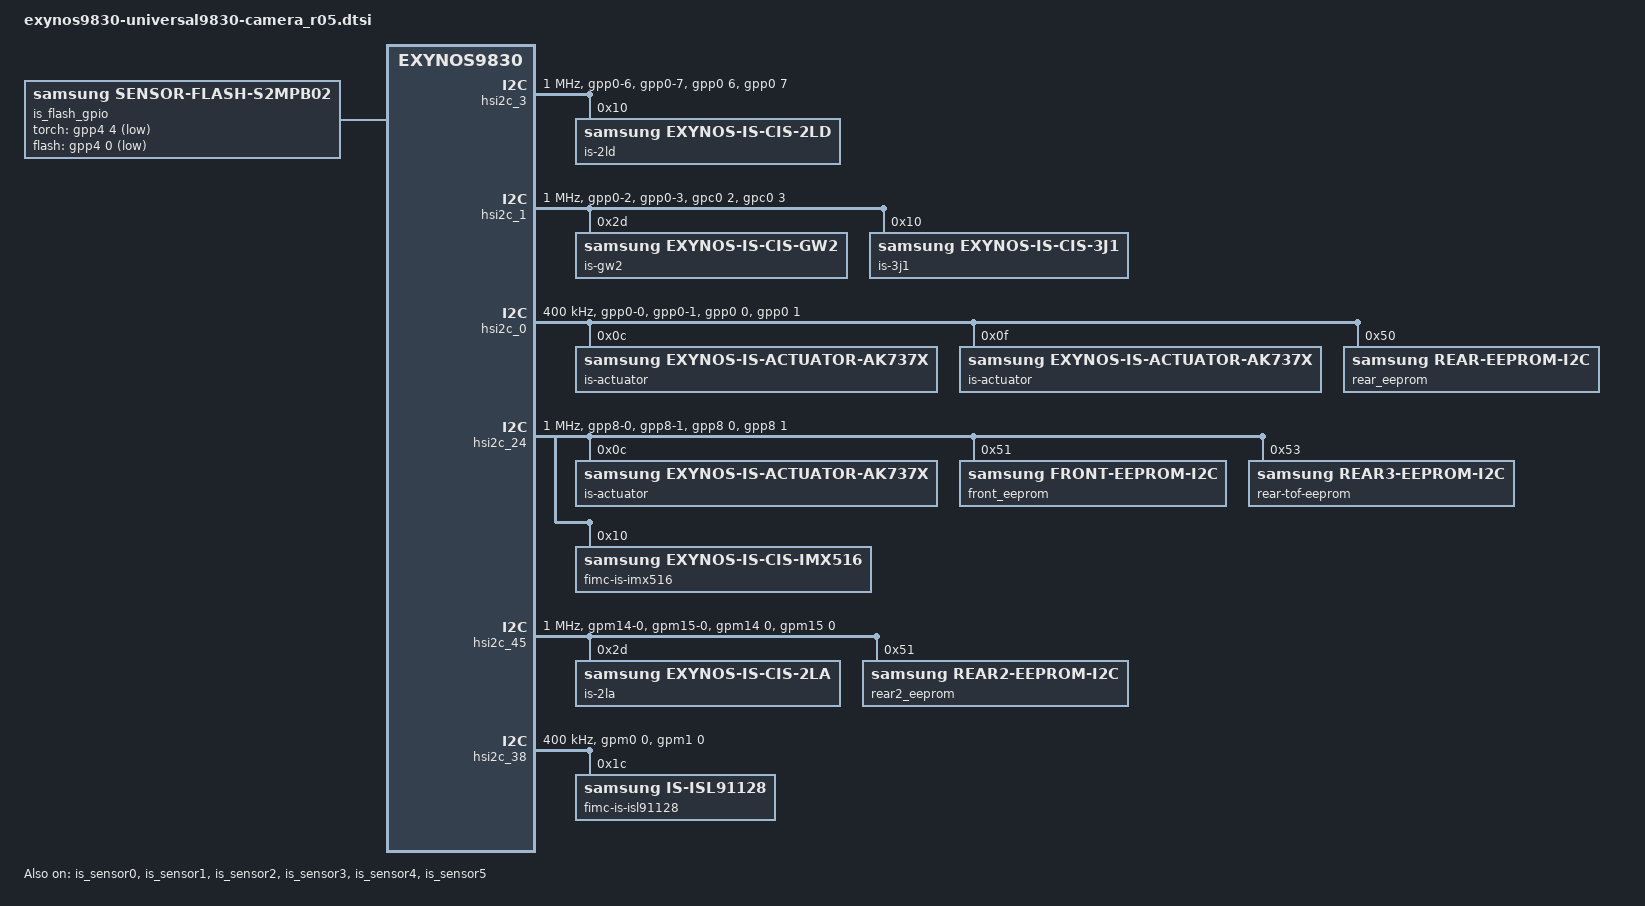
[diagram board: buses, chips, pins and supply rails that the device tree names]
/*
 * Samsung Exynos SoC series Pablo driver
 *
 * Copyright (c) 2019 Samsung Electronics Co., Ltd
 *
 * This program is free software; you can redistribute it and/or modify
 * it under the terms of the GNU General Public License version 2 as
 * published by the Free Software Foundation.
 */

#include <dt-bindings/camera/exynos_is_dt.h>
#include <dt-bindings/interrupt-controller/exynos9830.h>
#include <dt-bindings/clock/exynos9830.h>

#include "camera/module_2ld.dtsi"
#include "camera/module_3j1.dtsi"
#include "camera/module_2la.dtsi"
#include "camera/module_gw2.dtsi"
#include "camera/module_imx516.dtsi"

/ {
	fragment@camera {
		target-path = "/";
		__overlay__ {
			/* REAR CAMERA */
			is_sensor_2ld: is_sensor_2ld@20 {
				pinctrl-names = "pin0", "pin1", "pin2", "release";
				pinctrl-0 = <>;
				pinctrl-1 = <&sensor_mclk0_out>;
				pinctrl-2 = <&sensor_mclk0_fn>;
				pinctrl-3 = <>;

				/* board */
				position = <0>;	/* Rear:0. Front:1. Rear_sub:2. Secure:3. */
				id = <0>; /* is_sensor id */
				mclk_ch = <0>;
				sensor_i2c_ch = <0>; /* SENSOR_CONTROL_I2C0 */

				/* vendor */
				rom_type = <2>; /* ROM_TYPE_EEPROM */
				rom_id = <0>;
				rom_cal_index = <0>;

				/* peri */
				af {
					product_name = <18>; /* ACTUATOR_NAME_AK737X : ak7371 or ak7374 */
					i2c_ch = <1>; /* SENSOR_CONTROL_I2C1 */
				};

				flash {
					product_name = <11>; /* FLASH_GPIO */
				};

				ois {
					product_name = <100>; /* NOTHING */
				};

				mcu {
					product_name = <1>; /* STM32 */
					i2c_addr = <0x51>;
					i2c_ch = <1>; /* SENSOR_CONTROL_I2C1 */
				};

				aperture {
					product_name = <100>; /* NOTHING */
				};

				vc_extra {
					/* ex) statX = <stat_type, sensor_mode, max_width, max_height, max_element> */
					stat0 = </* not avaliable */>;									/* VC_BUF_DATA_TYPE_SENSOR_STAT1 */
					stat1 = </*VC_STAT_TYPE_PDP_1_1_PDAF_STAT0*/ 800 /*VC_SENSOR_MODE_2PD_MODE3*/ 102 512 84 1>;	/* VC_BUF_DATA_TYPE_GENERAL_STAT1 */
					stat2 = </* not avaliable */>;									/* VC_BUF_DATA_TYPE_SENSOR_STAT2 */
					stat3 = </*VC_STAT_TYPE_PDP_1_1_PDAF_STAT1*/ 801 /*VC_SENSOR_MODE_2PD_MODE3*/ 102 512 84 1>;	/* VC_BUF_DATA_TYPE_GENERAL_STAT2 */
				};

				power_seq {
					use = <1>;
					gpio_mclk = <&gpc0 0 0x1>;

					scenario_normal_on {
						sensor_scenario = <SENSOR_SCENARIO_NORMAL>;
						gpio_scenario = <GPIO_SCENARIO_ON>;

						/* A start node number should be over the 10 for reserved number 0~9. */
						/* pname = "name"; pin = <act value delay voltage>; gpio = <gpx# # 0x1>; */
						20 { pname = "VDDIO_1.8V_CAM"; pin = <PIN_REGULATOR 1 300>; share = <SRT_ACQUIRE SHARED_PIN6 1>; };
						85 { pname = "VDD_VM_2.8V_OIS"; pin = <PIN_REGULATOR 1 100>; share = <SRT_ACQUIRE SHARED_PIN3 1>; };
						86 { pname = "VDDD_1.8V_OIS"; pin = <PIN_REGULATOR 1 0>; share = <SRT_ACQUIRE SHARED_PIN2 1>; };
						100 { pname = "pin"; pin = <PIN_FUNCTION 2 0>; share = <SRT_ACQUIRE SHARED_PIN0 1>; };
						110 { pname = "MCLK"; pin = <PIN_MCLK 1 1500>; share = <SRT_ACQUIRE SHARED_PIN8 1>; };
						125 { pname = "ois_rst high"; pin = <PIN_OUTPUT 1 20000>; gpio = <&gpp9 3 0x1>; share = <SRT_ACQUIRE SHARED_PIN1 1>; };
					};

					scenario_vision_on {
						sensor_scenario = <SENSOR_SCENARIO_VISION>;
						gpio_scenario = <GPIO_SCENARIO_ON>;

						/* A start node number should be over the 10 for reserved number 0~9. */
						/* pname = "name"; pin = <act value delay voltage>; gpio = <gpx# # 0x1>; */
						20 { pname = "VDDIO_1.8V_CAM"; pin = <PIN_REGULATOR 1 300>; share = <SRT_ACQUIRE SHARED_PIN6 1>; };
						85 { pname = "VDD_VM_2.8V_OIS"; pin = <PIN_REGULATOR 1 100>; share = <SRT_ACQUIRE SHARED_PIN3 1>; };
						86 { pname = "VDDD_1.8V_OIS"; pin = <PIN_REGULATOR 1 0>; share = <SRT_ACQUIRE SHARED_PIN2 1>; };
						100 { pname = "pin"; pin = <PIN_FUNCTION 2 0>; share = <SRT_ACQUIRE SHARED_PIN0 1>; };
						110 { pname = "MCLK"; pin = <PIN_MCLK 1 1500>; share = <SRT_ACQUIRE SHARED_PIN8 1>; };
						125 { pname = "ois_rst high"; pin = <PIN_OUTPUT 1 20000>; gpio = <&gpp9 3 0x1>; share = <SRT_ACQUIRE SHARED_PIN1 1>; };
					};

					scenario_hw_init_normal_on {
						/* HW INIT (without ois power control) */
					};

					scenario_normal_off {
						sensor_scenario = <SENSOR_SCENARIO_NORMAL>;
						gpio_scenario = <GPIO_SCENARIO_OFF>;

						/* A start node number should be over the 10 for reserved number 0~9. */
						/* pname = "name"; pin = <act value delay voltage>; gpio = <gpx# # 0x1>; */
						60 { pname = "MCLK"; pin = <PIN_MCLK 0 0>; share = <SRT_RELEASE SHARED_PIN8 0>; };
						80 { pname = "pin"; pin = <PIN_FUNCTION 1 0>; share = <SRT_RELEASE SHARED_PIN0 0>; };
						105 { pname = "ois_rst low"; pin = <PIN_OUTPUT 0 0>; gpio = <&gpp9 3 0x1>; share = <SRT_RELEASE SHARED_PIN1 0>; };
						115 { pname = "VDDD_1.8V_OIS"; pin = <PIN_REGULATOR 0 0>; share = <SRT_RELEASE SHARED_PIN2 0>; };
						116 { pname = "VDD_VM_2.8V_OIS"; pin = <PIN_REGULATOR 0 0>; share = <SRT_RELEASE SHARED_PIN3 0>; };
						130 { pname = "VDDIO_1.8V_CAM"; pin = <PIN_REGULATOR 0 10>; share = <SRT_RELEASE SHARED_PIN6 0>; };
					};

					scenario_vision_off {
						sensor_scenario = <SENSOR_SCENARIO_VISION>;
						gpio_scenario = <GPIO_SCENARIO_OFF>;

						/* A start node number should be over the 10 for reserved number 0~9. */
						/* pname = "name"; pin = <act value delay voltage>; gpio = <gpx# # 0x1>; */
						60 { pname = "MCLK"; pin = <PIN_MCLK 0 0>; share = <SRT_RELEASE SHARED_PIN8 0>; };
						80 { pname = "pin"; pin = <PIN_FUNCTION 1 0>; share = <SRT_RELEASE SHARED_PIN0 0>; };
						105 { pname = "ois_rst low"; pin = <PIN_OUTPUT 0 0>; gpio = <&gpp9 3 0x1>; share = <SRT_RELEASE SHARED_PIN1 0>; };
						115 { pname = "VDDD_1.8V_OIS"; pin = <PIN_REGULATOR 0 0>; share = <SRT_RELEASE SHARED_PIN2 0>; };
						116 { pname = "VDD_VM_2.8V_OIS"; pin = <PIN_REGULATOR 0 0>; share = <SRT_RELEASE SHARED_PIN3 0>; };
						130 { pname = "VDDIO_1.8V_CAM"; pin = <PIN_REGULATOR 0 10>; share = <SRT_RELEASE SHARED_PIN6 0>; };
					};

					scenario_retention_on {
						sensor_scenario = <SENSOR_SCENARIO_NORMAL>;
						gpio_scenario = <GPIO_SCENARIO_SENSOR_RETENTION_ON>;

						/* A start node number should be over the 10 for reserved number 0~9. */
						/* pname = "name"; pin = <act value delay voltage>; gpio = <gpx# # 0x1>; */
						20 { pname = "MCLK"; pin = <PIN_MCLK 0 0>; share = <SRT_RELEASE SHARED_PIN8 0>; };
						40 { pname = "pin"; pin = <PIN_FUNCTION 1 0>; share = <SRT_RELEASE SHARED_PIN0 0>; };
						105 { pname = "ois_rst low"; pin = <PIN_OUTPUT 0 0>;  gpio = <&gpp9 3 0x1>; share = <SRT_RELEASE SHARED_PIN1 0>; };
						115 { pname = "VDD_VM_2.8V_OIS"; pin = <PIN_REGULATOR 0 0>; share = <SRT_RELEASE SHARED_PIN3 0>; };
						116 { pname = "VDDD_1.8V_OIS"; pin = <PIN_REGULATOR 0 0>; share = <SRT_RELEASE SHARED_PIN2 0>; };
					};

					scenario_hw_init_retention_on {
						/* RETENTION ON HW INIT(without ois power control) */
					};

					scenario_ois_factory_on {
					};

					scenario_ois_factory_off {
						sensor_scenario = <SENSOR_SCENARIO_OIS_FACTORY>;
						gpio_scenario = <GPIO_SCENARIO_OFF>;

						/* A start node number should be over the 10 for reserved number 0~9. */
						/* pname = "name"; pin = <act value dealy voltage>; gpio = <gpx# # 0x1>; */
						//10 { pname = "ois_rst low"; pin = <PIN_OUTPUT 0 0>; };//gpio = <&gpp9 3 0x1>; ;
						10 { pname = "ois_rst low"; pin = <PIN_OUTPUT 0 0>; gpio = <&gpp9 3 0x1>; };
					};

					scenario_read_rom_on {
					};

					scenario_read_rom_off {
					};
				};
			};

			/* Tele CAMERA */
			is_sensor_gw2: is_sensor_gw2@5A {
				pinctrl-names = "pin0", "pin1", "pin2", "release";
				pinctrl-0 = <>;
				pinctrl-1 = <&sensor_mclk0_out>;
				pinctrl-2 = <&sensor_mclk0_fn>;
				pinctrl-3 = <>;

				/* board */
				position = <2>; /* Rear:0. Front:1, Tele:2 */
				id = <2>; /* is_sensor id */
				mclk_ch = <0>;
				sensor_i2c_ch = <2>; /* SENSOR_CONTROL_I2C5 */

				/* vendor */
				rom_type = <2>; /* ROM_TYPE_EEPROM */
				rom_id = <0>;
				rom_cal_index = <1>;
				rom_dualcal_id = <0>;
				rom_dualcal_index = <0>;

				af {
					product_name = <18>; /* ACTUATOR_NAME_AK737X : ak7371 or ak7374 */
					i2c_ch = <3>; /* SENSOR_CONTROL_I2C1 */
				};

				flash {
					product_name = <11>; /* FLASH_GPIO */
				};

				preprocessor {
					product_name = <100>; /* NOTHING */
				};

				ois {
					product_name = <100>; /* NOTHING */
				};

				mcu {
					product_name = <1>; /* STM32 */
					i2c_addr = <0x51>;
					i2c_ch = <3>; /* SENSOR_CONTROL_I2C3 */
				};

				vc_extra {
					/* ex) statX = <stat_type, sensor_mode, max_width, max_height, max_element> */
					stat0 = </* not avaliable */>;
					stat1 = </* not avaliable */>;
					stat2 = </* not avaliable */>;
					stat3 = </* not avaliable */>;
				};

				power_seq {
					use = <1>;
					gpio_mclk = <&gpc0 0 0x1>;

					scenario_normal_on {
						sensor_scenario = <SENSOR_SCENARIO_NORMAL>;
						gpio_scenario = <GPIO_SCENARIO_ON>;

						/* A start node number should be over the 10 for reserved number 0~9. */
						/* pname = "name"; pin = <act value delay voltage>; gpio = <gpx# # 0x1>; */
						5 { pname = "S2MPB02_BUCK2"; pin = <PIN_REGULATOR 0 1>; share = <SRT_ACQUIRE SHARED_PIN7 1>; };
						6 { pname = "gpio_subcam_sel high"; pin = <PIN_OUTPUT 1 2000>; gpio = <&gpc0 5 0x1>; };
						35 { pname = "VDD_VM_2.8V_OIS"; pin = <PIN_REGULATOR 1 100>; share = <SRT_ACQUIRE SHARED_PIN3 1>; };
						36 { pname = "VDDD_1.8V_OIS"; pin = <PIN_REGULATOR 1 0>; share = <SRT_ACQUIRE SHARED_PIN2 1>; };
						40 { pname = "VDDIO_1.8V_CAM"; pin = <PIN_REGULATOR 1 100>; share = <SRT_ACQUIRE SHARED_PIN6 1>; };
						45 { pname = "VDDIO_1.8V_VT"; pin = <PIN_REGULATOR 1 0>; };
						70 { pname = "pin"; pin = <PIN_FUNCTION 2 0>; share = <SRT_ACQUIRE SHARED_PIN0 1>; };
						80 { pname = "MCLK"; pin = <PIN_MCLK 1 0>; share = <SRT_ACQUIRE SHARED_PIN8 1>; };
						95 { pname = "ois_rst high"; pin = <PIN_OUTPUT 1 20000>; gpio = <&gpp9 3 0x1>; share = <SRT_ACQUIRE SHARED_PIN1 1>; };
					};

					scenario_normal_off {
						sensor_scenario = <SENSOR_SCENARIO_NORMAL>;
						gpio_scenario = <GPIO_SCENARIO_OFF>;

						/* A start node number should be over the 10 for reserved number 0~9. */
						/* pname = "name"; pin = <act value delay voltage>; gpio = <gpx# # 0x1>; */
						5 { pname = "gpio_subcam_sel low"; pin = <PIN_OUTPUT 0 9>; gpio = <&gpc0 5 0x1>; };
						40 { pname = "VDDIO_1.8V_CAM"; pin = <PIN_REGULATOR 0 0>; share = <SRT_RELEASE SHARED_PIN6 0>; };
						55 { pname = "VDDIO_1.8V_VT"; pin = <PIN_REGULATOR 0 0>; };
						75 { pname = "ois_rst low"; pin = <PIN_OUTPUT 0 0>; gpio = <&gpp9 3 0x1>; share = <SRT_RELEASE SHARED_PIN1 0>; };
						76 { pname = "VDDD_1.8V_OIS"; pin = <PIN_REGULATOR 0 0>; share = <SRT_RELEASE SHARED_PIN2 0>; };
						80 { pname = "MCLK"; pin = <PIN_MCLK 0 0>; share = <SRT_RELEASE SHARED_PIN8 0>; };
						100 { pname = "pin"; pin = <PIN_FUNCTION 1 0>; share = <SRT_RELEASE SHARED_PIN0 0>; };
						115 { pname = "S2MPB02_BUCK2"; pin = <PIN_REGULATOR 0 0>; share = <SRT_RELEASE SHARED_PIN7 0>; };
					};

					scenario_vision_on {
						sensor_scenario = <SENSOR_SCENARIO_VISION>;
						gpio_scenario = <GPIO_SCENARIO_ON>;

						/* A start node number should be over the 10 for reserved number 0~9. */
						/* pname = "name"; pin = <act value delay voltage>; gpio = <gpx# # 0x1>; */
						5 { pname = "S2MPB02_BUCK2"; pin = <PIN_REGULATOR 0 1>; share = <SRT_ACQUIRE SHARED_PIN7 1>; };
						6 { pname = "gpio_subcam_sel high"; pin = <PIN_OUTPUT 1 2000>; gpio = <&gpc0 5 0x1>; };
						35 { pname = "VDD_VM_2.8V_OIS"; pin = <PIN_REGULATOR 1 100>; share = <SRT_ACQUIRE SHARED_PIN3 1>; };
						36 { pname = "VDDD_1.8V_OIS"; pin = <PIN_REGULATOR 1 0>; share = <SRT_ACQUIRE SHARED_PIN2 1>; };
						40 { pname = "VDDIO_1.8V_CAM"; pin = <PIN_REGULATOR 1 100>; share = <SRT_ACQUIRE SHARED_PIN6 1>; };
						45 { pname = "VDDIO_1.8V_VT"; pin = <PIN_REGULATOR 1 0>; };
						70 { pname = "pin"; pin = <PIN_FUNCTION 2 0>; share = <SRT_ACQUIRE SHARED_PIN0 1>; };
						80 { pname = "MCLK"; pin = <PIN_MCLK 1 0>; share = <SRT_ACQUIRE SHARED_PIN8 1>; };
						95 { pname = "ois_rst high"; pin = <PIN_OUTPUT 1 20000>; gpio = <&gpp9 3 0x1>; share = <SRT_ACQUIRE SHARED_PIN1 1>; };
					};

					scenario_vision_off {
						sensor_scenario = <SENSOR_SCENARIO_VISION>;
						gpio_scenario = <GPIO_SCENARIO_OFF>;

						/* A start node number should be over the 10 for reserved number 0~9. */
						/* pname = "name"; pin = <act value delay voltage>; gpio = <gpx# # 0x1>; */
						5 { pname = "gpio_subcam_sel low"; pin = <PIN_OUTPUT 0 9>; gpio = <&gpc0 5 0x1>; };
						40 { pname = "VDDIO_1.8V_CAM"; pin = <PIN_REGULATOR 0 0>; share = <SRT_RELEASE SHARED_PIN6 0>; };
						55 { pname = "VDDIO_1.8V_VT"; pin = <PIN_REGULATOR 0 0>; };
						75 { pname = "ois_rst low"; pin = <PIN_OUTPUT 0 0>; gpio = <&gpp9 3 0x1>; share = <SRT_RELEASE SHARED_PIN1 0>; };
						76 { pname = "VDDD_1.8V_OIS"; pin = <PIN_REGULATOR 0 0>; share = <SRT_RELEASE SHARED_PIN2 0>; };
						80 { pname = "MCLK"; pin = <PIN_MCLK 0 0>; share = <SRT_RELEASE SHARED_PIN8 0>; };
						100 { pname = "pin"; pin = <PIN_FUNCTION 1 0>; share = <SRT_RELEASE SHARED_PIN0 0>; };
						115 { pname = "S2MPB02_BUCK2"; pin = <PIN_REGULATOR 0 0>; share = <SRT_RELEASE SHARED_PIN7 0>; };
					};
				};
			};

			/* Ultra Wide CAMERA */
			is_sensor_2la: is_sensor_2la@2D {
				pinctrl-names = "pin0", "pin1", "pin2", "release";
				pinctrl-0 = <>;
				pinctrl-1 = <&sensor_mclk4_out>;
				pinctrl-2 = <&sensor_mclk4_fn>;
				pinctrl-3 = <>;

				/* board */
				position = <4>; /* Rear:0. Front:1, Tele:2 */
				id = <4>; /* is_sensor id */
				mclk_ch = <3>;
				sensor_i2c_ch = <4>; /* SENSOR_CONTROL_I2C5 */

				/* vendor */
				rom_type = <2>; /* ROM_TYPE_EEPROM */
				rom_id = <2>;
				rom_cal_index = <0>;
				rom_dualcal_id = <0>;
				rom_dualcal_index = <0>;

				af {
					product_name = <100>; /* NOTHING */
				};

				flash {
					product_name = <100>; /* NOTHING */
				};

				preprocessor {
					product_name = <100>; /* NOTHING */
				};

				ois {
					product_name = <100>; /* NOTHING */
				};

				power_seq {
					use = <1>;
					gpio_mclk = <&gpc0 3 0x1>;

					scenario_normal_on {
						sensor_scenario = <SENSOR_SCENARIO_NORMAL>;
						gpio_scenario = <GPIO_SCENARIO_ON>;

						/* A start node number should be over the 10 for reserved number 0~9. */
						/* pname = "name"; pin = <act value delay voltage>; gpio = <gpx# # 0x1>; */
						5 { pname = "S2MPB02_BUCK2"; pin = <PIN_REGULATOR 0 1>; share = <SRT_ACQUIRE SHARED_PIN7 1>; };
					};

					scenario_normal_off {
						sensor_scenario = <SENSOR_SCENARIO_NORMAL>;
						gpio_scenario = <GPIO_SCENARIO_OFF>;

						/* A start node number should be over the 10 for reserved number 0~9. */
						/* pname = "name"; pin = <act value delay voltage>; gpio = <gpx# # 0x1>; */
						95 { pname = "S2MPB02_BUCK2"; pin = <PIN_REGULATOR 0 0>; share = <SRT_RELEASE SHARED_PIN7 0>; };
					};

					scenario_vision_on {
						sensor_scenario = <SENSOR_SCENARIO_VISION>;
						gpio_scenario = <GPIO_SCENARIO_ON>;

						/* A start node number should be over the 10 for reserved number 0~9. */
						/* pname = "name"; pin = <act value delay voltage>; gpio = <gpx# # 0x1>; */
						5 { pname = "S2MPB02_BUCK2"; pin = <PIN_REGULATOR 0 1>; share = <SRT_ACQUIRE SHARED_PIN7 1>; };
						10 { pname = "sen_rst low"; pin = <PIN_OUTPUT 0 0>; gpio = <&gpm33 0 0x1>; };
						20 { pname = "VDDA_2.8V_WIDESUB"; pin = <PIN_REGULATOR 1 0>; };
						30 { pname = "VDDD_1.05V_WIDESUB"; pin = <PIN_REGULATOR 1 0>; };
						40 { pname = "VDDIO_1.8V_WIDESUB"; pin = <PIN_REGULATOR 1 0>; };
						50 { pname = "on_i2c"; pin = <PIN_I2C 1 10>; };
						60 { pname = "sen_rst high"; pin = <PIN_OUTPUT 1 10>; gpio = <&gpm33 0 0x1>; };
						70 { pname = "pin"; pin = <PIN_FUNCTION 2 0>; };
						80 { pname = "MCLK"; pin = <PIN_MCLK 1 2000>; };
					};

					scenario_vision_off {
						sensor_scenario = <SENSOR_SCENARIO_VISION>;
						gpio_scenario = <GPIO_SCENARIO_OFF>;

						/* A start node number should be over the 10 for reserved number 0~9. */
						/* pname = "name"; pin = <act value delay voltage>; gpio = <gpx# # 0x1>; */
						10 { pname = "sen_rst low"; pin = <PIN_OUTPUT 0 0>; gpio = <&gpm33 0 0x1>; };
						20 { pname = "off_i2c"; pin = <PIN_I2C 0 0>; };
						30 { pname = "VDDIO_1.8V_WIDESUB"; pin = <PIN_REGULATOR 0 0>; };
						40 { pname = "VDDD_1.05V_WIDESUB"; pin = <PIN_REGULATOR 0 0>; };
						50 { pname = "VDDA_2.8V_WIDESUB"; pin = <PIN_REGULATOR 0 0>; };
						60 { pname = "MCLK"; pin = <PIN_MCLK 0 0>; };
						70 { pname = "pin"; pin = <PIN_FUNCTION 0 0>; };
						80 { pname = "pin"; pin = <PIN_FUNCTION 1 0>; };
						90 { pname = "pin"; pin = <PIN_FUNCTION 0 0>; };
						95 { pname = "S2MPB02_BUCK2"; pin = <PIN_REGULATOR 0 0>; share = <SRT_RELEASE SHARED_PIN7 0>; };
					};

					scenario_read_rom_off {
					};
				};
			};

			/* FRONT CAMERA */
			is_sensor_3j1: is_sensor_3j1@10 {
				pinctrl-names = "pin0", "pin1", "pin2", "release";
				pinctrl-0 = <>;
				pinctrl-1 = <&sensor_mclk2_out>;
				pinctrl-2 = <&sensor_mclk2_fn>;
				pinctrl-3 = <>;

				/* board */
				position = <1>;	/* Rear:0. Front:1. Rear_sub:2. Secure:3. */
				id = <1>; /* is_sensor id */
				mclk_ch = <1>;
				sensor_i2c_ch = <1>; /* SENSOR_CONTROL_I2C4 */

				/* vendor */
				rom_type = <2>; /* ROM_TYPE_EEPROM */
				rom_id = <1>;
				rom_cal_index = <0>;

				/* peri*/
				af {
					product_name = <18>; /* ACTUATOR_NAME_AK737X */
					i2c_ch = <5>; /* SENSOR_CONTROL_I2C5 */
				};

				flash {
					product_name = <100>; /* NOTHING */
				};

				ois {
					product_name = <100>; /* NOTHING */
				};

				vc_extra {
					/* ex) statX = <stat_type, sensor_mode, max_width, max_height, max_element> */
					stat0 = </* not avaliable */>;									/* VC_BUF_DATA_TYPE_SENSOR_STAT1 */
					stat1 = </*VC_STAT_TYPE_PDP_1_1_PDAF_STAT0*/ 800 /*VC_SENSOR_MODE_2PD_MODE3*/ 102 512 84 1>;	/* VC_BUF_DATA_TYPE_GENERAL_STAT1 */
					stat2 = </* not avaliable */>;									/* VC_BUF_DATA_TYPE_SENSOR_STAT2 */
					stat3 = </*VC_STAT_TYPE_PDP_1_1_PDAF_STAT1*/ 801 /*VC_SENSOR_MODE_2PD_MODE3*/ 102 512 84 1>;	/* VC_BUF_DATA_TYPE_GENERAL_STAT2 */
				};

				power_seq {
					use = <1>;
					gpio_mclk = <&gpc0 1 0x1>;

					scenario_normal_on {
						sensor_scenario = <SENSOR_SCENARIO_NORMAL>;
						gpio_scenario = <GPIO_SCENARIO_ON>;

						/* A start node number should be over the 10 for reserved number 0~9. */
						/* pname = "name"; pin = <act value delay voltage>; gpio = <gpx# # 0x1>; */
						5 { pname = "S2MPB02_BUCK2"; pin = <PIN_REGULATOR 1 0>; };
						6 { pname = "gpio_subcam_sel high"; pin = <PIN_OUTPUT 0 2000>; gpio = <&gpc0 5 0x1>; };
						60 { pname = "rst_high"; pin = <PIN_OUTPUT 1 0>; gpio = <&gpm11 0 0x1>; };
						70 { pname = "pin"; pin = <PIN_FUNCTION 2 0>; share = <SRT_ACQUIRE SHARED_PIN5 1>; };
						80 { pname = "MCLK"; pin = <PIN_MCLK 1 9000>; share = <SRT_ACQUIRE SHARED_PIN9 1>; };
					};

					scenario_normal_off {
						sensor_scenario = <SENSOR_SCENARIO_NORMAL>;
						gpio_scenario = <GPIO_SCENARIO_OFF>;

						/* A start node number should be over the 10 for reserved number 0~9. */
						/* pname = "name"; pin = <act value delay voltage>; gpio = <gpx# # 0x1>; */
						5 { pname = "gpio_subcam_sel low"; pin = <PIN_OUTPUT 0 9>; gpio = <&gpc0 5 0x1>; };
						10 { pname = "MCLK"; pin = <PIN_MCLK 0 1>; share = <SRT_RELEASE SHARED_PIN9 0>; };
						30 { pname = "pin"; pin = <PIN_FUNCTION 1 0>; share = <SRT_RELEASE SHARED_PIN5 0>; };
						50 { pname = "rst_low"; pin = <PIN_OUTPUT 0 0>; gpio = <&gpm11 0 0x1>; };
						105 { pname = "S2MPB02_BUCK2"; pin = <PIN_REGULATOR 0 0>; };
					};

					scenario_vision_on {
						sensor_scenario = <SENSOR_SCENARIO_VISION>;
						gpio_scenario = <GPIO_SCENARIO_ON>;

						/* A start node number should be over the 10 for reserved number 0~9. */
						/* pname = "name"; pin = <act value delay voltage>; gpio = <gpx# # 0x1>; */
						5 { pname = "S2MPB02_BUCK2"; pin = <PIN_REGULATOR 1 0>; };
						6 { pname = "gpio_subcam_sel high"; pin = <PIN_OUTPUT 0 2000>; gpio = <&gpc0 5 0x1>; };
						60 { pname = "rst_high"; pin = <PIN_OUTPUT 1 0>; gpio = <&gpm11 0 0x1>; };
						70 { pname = "pin"; pin = <PIN_FUNCTION 2 0>; share = <SRT_ACQUIRE SHARED_PIN5 1>; };
						80 { pname = "MCLK"; pin = <PIN_MCLK 1 9000>; share = <SRT_ACQUIRE SHARED_PIN9 1>; };
					};

					scenario_vision_off {
						sensor_scenario = <SENSOR_SCENARIO_VISION>;
						gpio_scenario = <GPIO_SCENARIO_OFF>;

						/* A start node number should be over the 10 for reserved number 0~9. */
						/* pname = "name"; pin = <act value delay voltage>; gpio = <gpx# # 0x1>; */
						5 { pname = "gpio_subcam_sel low"; pin = <PIN_OUTPUT 0 9>; gpio = <&gpc0 5 0x1>; };
						10 { pname = "MCLK"; pin = <PIN_MCLK 0 1>; share = <SRT_RELEASE SHARED_PIN9 0>; };
						30 { pname = "pin"; pin = <PIN_FUNCTION 1 0>; share = <SRT_RELEASE SHARED_PIN5 0>; };
						50 { pname = "rst_low"; pin = <PIN_OUTPUT 0 0>; gpio = <&gpm11 0 0x1>; };
						105 { pname = "S2MPB02_BUCK2"; pin = <PIN_REGULATOR 0 0>; };
					};
				};
			};

			/* REAR TOF */
			is_sensor_imx516: is_sensor_imx516@10 {
				pinctrl-names = "pin0", "pin1", "pin2", "release";
				pinctrl-0 = <>;
				pinctrl-1 = <&sensor_mclk3_out>;
				pinctrl-2 = <&sensor_mclk3_fn>;
				pinctrl-3 = <>;

				position = <8>; /* Rear:0. Front:1, Tele:2 */
				id = <3>; /* fimc_is_sensor id */
				mclk_ch = <2>;
				sensor_i2c_ch = <6>; /* SENSOR_CONTROL_I2C6 */

				rom_type = <2>; /* ROM_TYPE_EEPROM */
				rom_id = <4>;
				rom_cal_index = <0>;
				rom_dualcal_id = <0>;
				rom_dualcal_index = <2>;

				af {
					product_name = <100>;  /* NOTHING */
				};

				flash {
					product_name = <100>;  /* NOTHING */
				};

				preprocessor {
					product_name = <100>; /* NOTHING */
				};

				ois {
					product_name = <100>; /* NOTHING */
				};

				power_seq {
					use = <1>;
					gpio_mclk = <&gpc0 2 0x1>;

					scenario_normal_on {
						sensor_scenario = <SENSOR_SCENARIO_VISION>;
						gpio_scenario = <GPIO_SCENARIO_ON>;

						/* A start node number should be over the 10 for reserved number 0~9. */
						/* pname = "name"; pin = <act value dealy voltage>; gpio = <gpx# # 0x1>; */
						5 { pname = "S2MPB02_BUCK2"; pin = <PIN_REGULATOR 1 0>; share = <SRT_ACQUIRE SHARED_PIN7 1>; };
						45 { pname = "VDDIO_1.8V_VT"; pin = <PIN_REGULATOR 1 0>; };
					};

					scenario_normal_off {
						sensor_scenario = <SENSOR_SCENARIO_VISION>;
						gpio_scenario = <GPIO_SCENARIO_OFF>;

						/* A start node number should be over the 10 for reserved number 0~9. */
						/* pname = "name"; pin = <act value dealy voltage>; gpio = <gpx# # 0x1>; */
						15 { pname = "VDDIO_1.8V_VT"; pin = <PIN_REGULATOR 0 0>; };
						125 { pname = "S2MPB02_BUCK2"; pin = <PIN_REGULATOR 0 0>; share = <SRT_RELEASE SHARED_PIN7 0>; };
					};

					scenario_read_rom_on {
						sensor_scenario = <SENSOR_SCENARIO_READ_ROM>;
						gpio_scenario = <GPIO_SCENARIO_ON>;

						/* A start node number should be over the 10 for reserved number 0~9. */
						/* pname = "name"; pin = <act value dealy voltage>; gpio = <gpx# # 0x1>; */
						15 { pname = "VDDIO_1.8V_VT"; pin = <PIN_REGULATOR 1 0>; };
					};

					scenario_read_rom_off {
						sensor_scenario = <SENSOR_SCENARIO_READ_ROM>;
						gpio_scenario = <GPIO_SCENARIO_OFF>;

						/* A start node number should be over the 10 for reserved number 0~9. */
						/* pname = "name"; pin = <act value dealy voltage>; gpio = <gpx# # 0x1>; */
						15 { pname = "VDDIO_1.8V_VT"; pin = <PIN_REGULATOR 0 0>; };
					};
				};
			};

			is_flash_gpio: is-flash-gpio@0 {
				compatible = "samsung,sensor-flash-s2mpb02";
				id = <0 2 4>;
				status = "okay";

				torch-gpio = <&gpp4 4 0x1>;
				flash-gpio = <&gpp4 0 0x1>;
			};
		}; /* end of __overlay__ */
	}; /* end of fragment */
}; /* end of root */

/***** reference symbol node *****/
&pinctrl_1 {
	/* REAR3 */
	/* No pull-up resistor, use internal one */
	hsi2c45_bus: hsi2c3-bus {
		samsung,pins = "gpm14-0", "gpm15-0";
		samsung,pin-function = <3>;
		samsung,pin-pud = <3>;
		samsung,pin-drv = <0>;
	};

	hsi2c45_bus_in: hsi2c45_bus-in {
		samsung,pins = "gpm14-0", "gpm15-0";
		samsung,pin-function = <0>;
		samsung,pin-pud = <0>;
		samsung,pin-drv = <0>;
	};
};

&pinctrl_4 {
	/* REAR AF*/
	hsi2c0_bus_in: hsi2c0-bus-in {
		samsung,pins = "gpp0-0", "gpp0-1";
		samsung,pin-function = <0>;
		samsung,pin-pud = <0>;
		samsung,pin-drv = <0>;
	};

	/* FRONT */
	/* No pull-up resistor, use internal one */
	hsi2c1_bus: hsi2c1-bus {
		samsung,pin-pud = <3>;
	};

	hsi2c1_bus_in: hsi2c1-bus-in {
		samsung,pins = "gpp0-2", "gpp0-3";
		samsung,pin-function = <0>;
		samsung,pin-pud = <0>;
		samsung,pin-drv = <0>;
	};

	/* REAR WIDE */
	/* No pull-up resistor, use internal one */
	hsi2c3_bus: hsi2c3-bus {
		samsung,pin-pud = <3>;
	};

	hsi2c3_bus_in: hsi2c3-bus-in {
		samsung,pins = "gpp0-6", "gpp0-7";
		samsung,pin-function = <0>;
		samsung,pin-pud = <0>;
		samsung,pin-drv = <0>;
	};

	/* REAR TELE */
	/* No pull-up resistor, use internal one */
	hsi2c5_bus: hsi2c5-bus {
		samsung,pin-pud = <3>;
	};

	hsi2c5_bus_in: hsi2c5-bus-in {
		samsung,pins = "gpp1-2", "gpp1-3";
		samsung,pin-function = <0>;
		samsung,pin-pud = <0>;
		samsung,pin-drv = <0>;
	};
};

&pinctrl_5 {
	/* FRONT AF*/
	hsi2c24_bus_in: hsi2c24-bus-in {
		samsung,pins = "gpp8-0", "gpp8-1";
		samsung,pin-function = <0>;
		samsung,pin-pud = <0>;
		samsung,pin-drv = <0>;
	};
};

&hsi2c_3 {
	#address-cells = <1>;
	#size-cells = <0>;
	gpios = <&gpp0 6 0 &gpp0 7 0>;
	status = "okay";
	clock-frequency = <1000000>;
	samsung,reset-before-trans;
	samsung,fast-plus-mode;

	pinctrl-names = "default","on_i2c","off_i2c";
	pinctrl-0 = <&hsi2c3_bus_in>;
	pinctrl-1 = <&hsi2c3_bus>;
	pinctrl-2 = <&hsi2c3_bus_in>;

	is-2ld@10 {
		compatible = "samsung,exynos-is-cis-2ld";
		reg = <0x10>; /* 1 bit right shift */
		id = <0>; /* matching is_sensor id */
		setfile = "default";
		use_initial_ae; /* for initial AE */
		rev_reg = <0x0002 2 0xA102>;
	};
};

&hsi2c_1 {
	#address-cells = <1>;
	#size-cells = <0>;
	gpios = <&gpc0 2 0 &gpc0 3 0>;
	status = "okay";
	clock-frequency = <1000000>;
	samsung,reset-before-trans;
	samsung,fast-plus-mode;

	pinctrl-names = "default","on_i2c","off_i2c";
	pinctrl-0 = <&hsi2c1_bus_in>;
	pinctrl-1 = <&hsi2c1_bus>;
	pinctrl-2 = <&hsi2c1_bus_in>;

	is-gw2@2D {
		compatible = "samsung,exynos-is-cis-gw2";
		reg = <0x2D>; /* 1 bit right shift */
		id = <2>; /* matching is_sensor id */
		setfile = "setA";
		use_initial_ae; /* for initial AE */
		rev_reg = <0x0002 2 0xA301>;
	};

	is-3j1@10 {
		compatible = "samsung,exynos-is-cis-3j1";
		reg = <0x10>; /* 1 bit right shift */
		id = <1>; /* matching is_sensor id */
		setfile = "default";
		rev_reg = <0x0002 2 0xA101>;
	};
};

&hsi2c_0 {
	#address-cells = <1>;
	#size-cells = <0>;
	gpios = <&gpp0 0 0 &gpp0 1 0>;
	status = "okay";
	clock-frequency = <400000>;
	samsung,reset-before-trans;

	pinctrl-names = "default","on_i2c","off_i2c";
	pinctrl-0 = <&hsi2c0_bus_in>;
	pinctrl-1 = <&hsi2c0_bus>;
	pinctrl-2 = <&hsi2c0_bus_in>;

	is-actuator@0C { /* wide AF */
		compatible = "samsung,exynos-is-actuator-ak737x";
		reg = <0x0C>;
		id = <0>; /* matching is_sensor id */
		/* AK737x: addr 0xF3, data 0x0E */
		vendor_product_id = <0xF3 0x0E 0xF3 0x13 0xF3 0x00>;
		vendor_first_pos = <120>;
		vendor_first_delay = <2000>;
		vendor_use_sleep_mode;
	};

	is-actuator@0F { /* tele AF */
		compatible = "samsung,exynos-is-actuator-ak737x";
		reg = <0x0F>;
		id = <2>; /* matching sensor id */
		/* AK7377: addr 0xF3, data 0x0E */
		vendor_product_id = <0xF3 0x0E 0xF3 0x13 0xF3 0x00>;
		vendor_first_pos = <120>;
		vendor_first_delay = <2000>;
		vendor_use_sleep_mode;
	};

	rear_eeprom@50 {
		compatible = "samsung,rear-eeprom-i2c";
		reg = <0x50>;
		rom_power_position = <0>;
		rom_size = <0x10000>;
		cal_map_es_version = <10>;
		camera_module_es_version = "A";
		/*skip_cal_loading;*/
		/* Beyond_Rear_Cal_Map_V010_20180709_for_ALL */
		/* 0 header */
		header_crc_check_list = <0x0000 0x01FB 0x01FC>;
		/* 0 master LSC F1.5 */
		/* 1 master LSC F2.4 */
		/* 2 master all */
		crc_check_list = <0x0200 0x1BFB 0x1BFC
				0x1C00 0x35FB 0x35FC
				0x4400 0x75DF 0x75FC>;
		/* 0 u-wide dual cal data */
		/* 1 tele LSC */
		/* 2 tele dual cal data */
		dual_crc_check_list = <0x7600 0x7EFB 0x7EFC
					0x7F00 0x98FB 0x98FC
					0xA000 0xB7DF 0xB7FC>;
		/* Master */
		rom_header_version_start_addr = <0x50>;
		rom_header_cal_data_start_addr = <0x200>;
		rom_header_cal_map_ver_start_addr = <0x70>;
		rom_header_isp_setfile_ver_start_addr = <0x74>;
		rom_header_project_name_start_addr = <0x7E>;
		rom_header_module_id_addr = <0xAE>; /* 0xA8 + reserved bytes */
		rom_header_sensor_id_addr = <0xB8>;
		rom_header_mtf_data_addr = <0xE0>;
		rom_header_f2_mtf_data_addr = <0x116>;
		rom_awb_master_addr = <0x7450>;
		rom_awb_module_addr = <0x7474>;
		rom_af_cal_macro_addr = <0x7430>;
		rom_af_cal_d50_addr = <0x7428>;
		rom_af_cal_pan_addr = <0x7424>;
		/* Slave 0 */
		rom_header_sensor2_version_start_addr = <0x40>;
		rom_header_sensor2_id_addr = <0xC8>;
		rom_header_sensor2_mtf_data_addr = <0x14C>;
		rom_sensor2_awb_master_addr = <0xAE60>;
		rom_sensor2_awb_module_addr = <0xAE84>;
		rom_sensor2_af_cal_d50_addr = <0xAE38>;
		rom_sensor2_af_cal_pan_addr = <0xAE34>;
		/* Dual cal slave 0 - Ultra wide */
		rom_dualcal_slave0_start_addr = <0x7600>;
		rom_dualcal_slave0_size = <0x800>; /* 2048 */
		/* x y z sx sy */
		/* range max_err avg_err dll_version*/
		rom_dualcal_slave0_tilt_list = <0x7660 0x7664 0x7668 0x76C0 0x76C4
						0x7DE0 0x7DE4 0x7DE8 0x7600>;
		/* Dual cal slave 1 - Tele */
		rom_dualcal_slave1_start_addr = <0xAF10>;
		rom_dualcal_slave1_size = <0x800>; /* 2048 */
		/* x y z sx sy */
		/* range max_err avg_err dll_version*/
		rom_dualcal_slave1_tilt_list = <0xAF70 0xAF74 0xAF78 0xAFD0 0xAFD4
						0xB6F0 0xB6F4 0xB6F8 0xAF10>;

		/* sensor ois - xgg ygg xcoef ycoef xsupper ysupper calmark */
		/* sensor2 ois - xgg ygg xcoef ycoef xsupper ysupper calmark */
		rom_ois_list = <0x7550 0x7554 0xB625 0xB627 0x7578 0x757A 0x7570
				0xB730 0xB734 0xB629 0xB62B 0xB758 0xB75A 0xB750>;
	};
};

&hsi2c_24 {
	#address-cells = <1>;
	#size-cells = <0>;
	gpios = <&gpp8 0 0 &gpp8 1 0>;
	status = "okay";
	clock-frequency = <1000000>;
	samsung,reset-before-trans;
	samsung,fast-plus-mode;

	pinctrl-names = "default","on_i2c","off_i2c";
	pinctrl-0 = <&hsi2c24_bus_in>;
	pinctrl-1 = <&hsi2c24_bus>;
	pinctrl-2 = <&hsi2c24_bus_in>;

	is-actuator@0C {
		compatible = "samsung,exynos-is-actuator-ak737x";
		reg = <0x0C>;
		id = <1>; /* matching is_sensor id */
		/* AK737x: addr 0xF3, data 0x0E */
		vendor_product_id = <0xF3 0x0E>;
		vendor_first_pos = <120>;
		vendor_first_delay = <2000>;
	};

	front_eeprom@51 {
		compatible = "samsung,front-eeprom-i2c";
		reg = <0x51>;
		rom_power_position = <1>;
		rom_size = <0x4000>;
		cal_map_es_version = <4>;
		camera_module_es_version = "A";
		/*skip_cal_loading;*/
		/* Beyond_Front_Cal_Map_V004_20180801_for_LSI */
		/* 0 header */
		header_crc_check_list = <0x0000 0x015F 0x01FC>;
		/* 0 master */
		crc_check_list = <0x0200 0x34DF 0x34FC>;
		/* 0 dual */
		dual_crc_check_list = <0x3500 0x39DF 0x39FC>;
		/* Master */
		rom_header_version_start_addr = <0x30>;
		rom_header_cal_data_start_addr = <0x200>;
		rom_header_cal_map_ver_start_addr = <0x50>;
		/* rom_header_isp_setfile_ver_start_addr = <>; */
		rom_header_project_name_start_addr = <0x5C>;
		rom_header_module_id_addr = <0xAE>; /* 0xA8 + reserved bytes */
		rom_header_sensor_id_addr = <0x70>;
		rom_header_mtf_data_addr = <0xE0>;
		rom_awb_master_addr = <0x1A40>;
		rom_awb_module_addr = <0x1A4C>;
		rom_af_cal_macro_addr = <0x1A20>;
		rom_af_cal_pan_addr = <0x1A14>;
		/* Slave 0 */
		rom_header_sensor2_version_start_addr = <0x40>;
		rom_header_sensor2_id_addr = <0x80>;
		rom_header_sensor2_mtf_data_addr = <0x116>;
		/* rom_sensor2_awb_master_addr = <0x0>;*/ /* use default awb cal */
		/* rom_sensor2_awb_module_addr = <0x0>;*/ /* use default awb cal */
		/* Dual cal slave 0 - Front sub */
		rom_dualcal_slave0_start_addr = <0x3500>;
		rom_dualcal_slave0_size = <0x400>; /* 1024 */
		/* x y z sx sy */
		/* range max_err avg_err dll_version*/
		rom_dualcal_slave0_tilt_list = <0x3560 0x3564 0x3568 0x35C0 0x35C4
						0x38E4 0x38E8 0x38EC 0x3500>;
	};

	rear-tof-eeprom@53 {
		compatible = "samsung,rear3-eeprom-i2c";
		reg = <0x53>;

		rom_power_position = <8>;
		rom_size = <0x1900>;
		cal_map_es_version = <1>; /* TO DO 1 -> 2 */
		camera_module_es_version = "A";
		/* skip_header_loading; */
		/* skip_crc_check; */
		/*skip_cal_loading;*/

		/* davinci_REAR_TOF_Cal_Map_V003_190418 */
		/* 0 header */
		header_crc_check_list = <0x0000 0x00C9 0x00FC>;
		/* 1 cal all */
		crc_check_list = <0x0100 0x128F 0x18FC>;

		rom_header_cal_map_ver_start_addr = <0x50>;
		rom_header_version_start_addr = <0x40>;

		rom_header_module_id_addr = <0xAE>;
		rom_header_sensor_id_addr = <0xB8>;

		rom_tof_cal_size_addr = <0x0142 0x0402>; /*VGA CAL, QVGA CAL */
		rom_tof_cal_start_addr = <0x0100>;
		rom_tof_cal_uid_addr = <0x11A4 0x11B4>;  /*VGA UID, QVGA UID */
		rom_tof_cal_result_addr = <0x00CA>;
	};

	fimc-is-imx516@10 { /* rear tof */
		compatible = "samsung,exynos-is-cis-imx516";
		reg = <0x10>; /* 1 bit right shift */
		id = <3>; /* matching fimc_is_sensor id */
		setfile = "setA";
		status = "okay";
	};
};

&hsi2c_45 {
	#address-cells = <1>;
	#size-cells = <0>;
	gpios = <&gpm14 0 0 &gpm15 0 0>;
	status = "okay";
	clock-frequency = <1000000>;
	samsung,reset-before-trans;
	samsung,fast-plus-mode;

	pinctrl-names = "default","on_i2c","off_i2c";
	pinctrl-0 = <&hsi2c45_bus_in>;
	pinctrl-1 = <&hsi2c45_bus>;
	pinctrl-2 = <&hsi2c45_bus_in>;

	is-2la@2D {
		compatible = "samsung,exynos-is-cis-2la";
		reg = <0x2D>; /* 1 bit right shift */
		id = <4>; /* matching is_sensor id */
		setfile = "setA";
		status = "okay";
		use_initial_ae; /* for initial AE */
		/* rev_reg = <0x0002 2 0xA101>; */
	};

	rear2_eeprom@51 { /* Ultra wide eeprom */
		compatible = "samsung,rear2-eeprom-i2c";
		reg = <0x51>;

		rom_power_position = <4>;
		rom_size = <0x4000>;
		cal_map_es_version = <10>;
		camera_module_es_version = "A";
		/*skip_cal_loading;*/

		/* Beyond_Rear_Cal_Map_V010_20180709_for_ALL */
		/* 0 header */
		header_crc_check_list = <0x0000 0x00FB 0x00FC>;
		/* 0 master LSC */
		/* 1 master all */
		crc_check_list = <0x0100 0x1AFB 0x1AFC 0x2200 0x22DF 0x22FC>;

		/* Master */
		rom_header_version_start_addr = <0x40>;
		rom_header_cal_data_start_addr = <0x100>;
		rom_header_cal_map_ver_start_addr = <0x50>;
		rom_header_isp_setfile_ver_start_addr = <0x54>;
		rom_header_project_name_start_addr = <0x5E>;
		rom_header_module_id_addr = <0xAE>; /* 0xA8 + reserved bytes */
		rom_header_sensor_id_addr = <0xB8>;
		rom_header_mtf_data_addr = <0x66>;
		rom_awb_master_addr = <0x2200>;
		rom_awb_module_addr = <0x2224>;
	};
};

/* isl91128 */
&hsi2c_38 {
	#address-cells = <1>;
	#size-cells = <0>;
	gpios = <&gpm0 0 0 &gpm1 0 0>;
	status = "okay";
	clock-frequency = <400000>;
	samsung,reset-before-trans;

	pinctrl-names = "default","on_i2c","off_i2c";
	pinctrl-0 = <&hsi2c38_bus>;
	pinctrl-1 = <&hsi2c38_bus>;
	pinctrl-2 = <&hsi2c38_bus>;

	fimc-is-isl91128@1C { /* RTOF POWER */
		compatible = "samsung,is-isl91128";
		reg = <0x1C>; /* 1 bit right shift */
		voltage_option = <1>; /* 1 : ouput level is 3.35V */
	};
};

/* REAR CAMERA */
&is_sensor0 {
	#address-cells = <1>;
	#size-cells = <1>;
	scenario = <SENSOR_SCENARIO_NORMAL>;	/* Normal, Vision, OIS etc */
	id = <0>;
	csi_ch = <0>;
	dma_ch = <2 2 2 2
		0 0 0 0>;
	vc_ch = <0 1 2 3
		0 1 2 3>;
	flite_ch = <FLITE_ID_NOTHING>;
	is_bns = <0>;
	status = "okay";
	use_cphy = <1>;

	interrupts = <0 INTREQ__CSIS0 IRQ_TYPE_LEVEL_HIGH>, /*MIPI-CSI0 */
		<0 INTREQ__CSIS_DMA2 IRQ_TYPE_LEVEL_HIGH>,
		<0 INTREQ__CSIS_DMA2 IRQ_TYPE_LEVEL_HIGH>,
		<0 INTREQ__CSIS_DMA2 IRQ_TYPE_LEVEL_HIGH>,
		<0 INTREQ__CSIS_DMA2 IRQ_TYPE_LEVEL_HIGH>,
		<0 INTREQ__CSIS_DMA0 IRQ_TYPE_LEVEL_HIGH>,
		<0 INTREQ__CSIS_DMA0 IRQ_TYPE_LEVEL_HIGH>,
		<0 INTREQ__CSIS_DMA0 IRQ_TYPE_LEVEL_HIGH>,
		<0 INTREQ__CSIS_DMA0 IRQ_TYPE_LEVEL_HIGH>;
	interrupt-names = "csi",
		"mode0_VC0", "mode0_VC1","mode0_VC2","mode0_VC3",
		"mode1_VC0", "mode1_VC1","mode1_VC2","mode1_VC3";

	/* without frame ID decoder */
	sensor0_ch_mode0: sensor0-ch-mode0 {
		reg = <0x170C3000 0x100>, /* DMA2 VC0 */
			<0x170C3400 0x100>, /* DMA2 Common */
			<0x170C3100 0x100>, /* DMA2 VC1 */
			<0x170C3400 0x100>, /* DMA2 Common */
			<0x170C3200 0x100>, /* DMA2 VC2 */
			<0x170C3400 0x100>, /* DMA2 Common */
			<0x170C3300 0x100>, /* DMA2 VC3 */
			<0x170C3400 0x100>; /* DMA2 Common */
		mux_reg = <0x1702041C 0x4>; /* DMA2 input mux */
	};

	/* with frame ID decoder */
	sensor0_ch_mode1: sensor0-ch-mode1 {
		reg = <0x170C1000 0x100>, /* DMA0 VC0 */
			<0x170C1400 0x100>, /* DMA0 Common */
			<0x170C1100 0x100>, /* DMA0 VC1 */
			<0x170C1400 0x100>, /* DMA0 Common */
			<0x170C1200 0x100>, /* DMA0 VC2 */
			<0x170C1400 0x100>, /* DMA0 Common */
			<0x170C1300 0x100>, /* DMA0 VC3 */
			<0x170C1400 0x100>; /* DMA0 Common */
		mux_reg = <0x17020414 0x4>; /* DMA0 input mux */
	};
};

/* FRONT CAMERA */
&is_sensor1 {
	#address-cells = <1>;
	#size-cells = <1>;
	scenario = <SENSOR_SCENARIO_NORMAL>;    /* Normal, Vision, OIS etc */
	id = <1>;
	csi_ch = <1>;
	dma_ch = <1 1 1 1
		1 1 1 1>;
	vc_ch = <0 1 2 3
		0 1 2 3>;
	flite_ch = <FLITE_ID_NOTHING>;
	is_bns = <0>;
	status = "okay";

	interrupts = <0 INTREQ__CSIS1 IRQ_TYPE_LEVEL_HIGH>, /* MIPI-CSI1 */
		<0 INTREQ__CSIS_DMA1 IRQ_TYPE_LEVEL_HIGH>,
		<0 INTREQ__CSIS_DMA1 IRQ_TYPE_LEVEL_HIGH>,
		<0 INTREQ__CSIS_DMA1 IRQ_TYPE_LEVEL_HIGH>,
		<0 INTREQ__CSIS_DMA1 IRQ_TYPE_LEVEL_HIGH>,
		<0 INTREQ__CSIS_DMA1 IRQ_TYPE_LEVEL_HIGH>,
		<0 INTREQ__CSIS_DMA1 IRQ_TYPE_LEVEL_HIGH>,
		<0 INTREQ__CSIS_DMA1 IRQ_TYPE_LEVEL_HIGH>,
		<0 INTREQ__CSIS_DMA1 IRQ_TYPE_LEVEL_HIGH>;
	interrupt-names = "csi",
		"mode0_VC0", "mode0_VC1","mode0_VC2","mode0_VC3",
		"mode1_VC0", "mode1_VC1","mode1_VC2","mode1_VC3";

	/* without PAF HW */
	sensor1_ch_mode0: sensor1-ch-mode0 {
		reg = <0x170C2000 0x100>, /* DMA1 VC0 */
			<0x170C2400 0x100>, /* DMA1 Common */
			<0x170C2100 0x100>, /* DMA1 VC1 */
			<0x170C2400 0x100>, /* DMA1 Common */
			<0x170C2200 0x100>, /* DMA1 VC2 */
			<0x170C2400 0x100>, /* DMA1 Common */
			<0x170C2300 0x100>, /* DMA1 VC3 */
			<0x170C2400 0x100>; /* DMA1 Common */
		mux_reg = <0x17020418 0x4>; /* DMA1 input mux */
	};

	/* with PAF HW */
	sensor1_ch_mode1: sensor1-ch-mode1 {
		reg = <0x170C2000 0x100>, /* DMA1 VC0 */
			<0x170C2400 0x100>, /* DMA1 Common */
			<0x170C2100 0x100>, /* DMA1 VC1 */
			<0x170C2400 0x100>, /* DMA1 Common */
			<0x170C2200 0x100>, /* DMA1 VC2 */
			<0x170C2400 0x100>, /* DMA1 Common */
			<0x170C2300 0x100>, /* DMA1 VC3 */
			<0x170C2400 0x100>; /* DMA1 Common */
		mux_reg = <0x17020418 0x4>; /* DMA1 input mux */
	};
};

/* Tele CAMERA */
&is_sensor2 {
	#address-cells = <1>;
	#size-cells = <1>;
	scenario = <SENSOR_SCENARIO_NORMAL>;    /* Normal, Vision, OIS etc */
	id = <2>;
	csi_ch = <2>;
	dma_ch = <3 3 3 3
		3 3 3 3>;
	vc_ch = <0 1 2 3
		0 1 2 3>;
	flite_ch = <FLITE_ID_NOTHING>;
	is_bns = <0>;
	status = "okay";
	use_cphy = <1>;

	reg = <0x0 0x17050000 0x1000>, /* MIPI-CSI2 */
		<0x0 0x170D0000 0x10000>; /* PHY: M0S4S4S4S4S4S2 */
	reg-names = "csi", "phy";

	interrupts = <0 INTREQ__CSIS2 IRQ_TYPE_LEVEL_HIGH>, /* MIPI-CSI2 */
		<0 INTREQ__CSIS_DMA3 IRQ_TYPE_LEVEL_HIGH>,
		<0 INTREQ__CSIS_DMA3 IRQ_TYPE_LEVEL_HIGH>,
		<0 INTREQ__CSIS_DMA3 IRQ_TYPE_LEVEL_HIGH>,
		<0 INTREQ__CSIS_DMA3 IRQ_TYPE_LEVEL_HIGH>,
		<0 INTREQ__CSIS_DMA3 IRQ_TYPE_LEVEL_HIGH>,
		<0 INTREQ__CSIS_DMA3 IRQ_TYPE_LEVEL_HIGH>,
		<0 INTREQ__CSIS_DMA3 IRQ_TYPE_LEVEL_HIGH>,
		<0 INTREQ__CSIS_DMA3 IRQ_TYPE_LEVEL_HIGH>;
	interrupt-names = "csi",
		"mode0_VC0", "mode0_VC1","mode0_VC2","mode0_VC3",
		"mode1_VC0", "mode1_VC1","mode1_VC2","mode1_VC3";

	phys = <&mipi_phy_csis2_m0s4s4s4s4s4s2 0>;
	phy-names = "csis_dphy";

	/* without PAF HW */
	sensor2_ch_mode0: sensor2-ch-mode0 {
		reg = <0x170C4000 0x100>, /* DMA3 VC0 */
			<0x170C4400 0x100>, /* DMA3 Common */
			<0x170C4100 0x100>, /* DMA3 VC1 */
			<0x170C4400 0x100>, /* DMA3 Common */
			<0x170C4200 0x100>, /* DMA3 VC2 */
			<0x170C4400 0x100>, /* DMA3 Common */
			<0x170C4300 0x100>, /* DMA3 VC3 */
			<0x170C4400 0x100>; /* DMA3 Common */
		mux_reg = <0x17020420 0x4>; /* DMA3 input mux */
	};

	/* with PAF HW */
	sensor2_ch_mode1: sensor2-ch-mode1 {
		reg = <0x170C4000 0x100>, /* DMA3 VC0 */
			<0x170C4400 0x100>, /* DMA3 Common */
			<0x170C4100 0x100>, /* DMA3 VC1 */
			<0x170C4400 0x100>, /* DMA3 Common */
			<0x170C4200 0x100>, /* DMA3 VC2 */
			<0x170C4400 0x100>, /* DMA3 Common */
			<0x170C4300 0x100>, /* DMA3 VC3 */
			<0x170C4400 0x100>; /* DMA3 Common */
		mux_reg = <0x17020420 0x4>; /* DMA3 input mux */
	};
};

/* Reseved: FRONT SUB */
&is_sensor3 {
	#address-cells = <1>;
	#size-cells = <1>;
	scenario = <SENSOR_SCENARIO_NORMAL>;    /* Normal, Vision, OIS etc */
	id = <5>;
	csi_ch = <1>;
	dma_ch = <1 1 1 1>;
	vc_ch = <0 1 2 3>;
	flite_ch = <FLITE_ID_NOTHING>;
	is_bns = <0>;
	status = "okay";
};

/* ULTRA WIDE CAMERA */
&is_sensor4 {
	#address-cells = <1>;
	#size-cells = <1>;
	scenario = <SENSOR_SCENARIO_NORMAL>;    /* Normal, Vision, OIS etc */
	id = <4>;
	csi_ch = <4>;
	dma_ch = <0 0 0 0>;
	vc_ch = <0 1 2 3>;
	flite_ch = <FLITE_ID_NOTHING>;
	is_bns = <0>;
	status = "okay";
	use_cphy = <1>;

	reg = <0x0 0x17070000 0x1000>, /* MIPI-CSI4 */
			<0x0 0x170D0000 0x10000>; /* PHY: M0S4S4S4S4S4S2 */
	reg-names = "csi", "phy";

	phys = <&mipi_phy_csis4_m0s4s4s4s4s4s2 0>;
	phy-names = "csis_dphy";

	interrupts = <0 INTREQ__CSIS4 IRQ_TYPE_LEVEL_HIGH>, /* MIPI-CSI4 */
			<0 INTREQ__CSIS_DMA0 IRQ_TYPE_LEVEL_HIGH>,
			<0 INTREQ__CSIS_DMA0 IRQ_TYPE_LEVEL_HIGH>,
			<0 INTREQ__CSIS_DMA0 IRQ_TYPE_LEVEL_HIGH>,
			<0 INTREQ__CSIS_DMA0 IRQ_TYPE_LEVEL_HIGH>;
	interrupt-names = "csi",
			"mode0_VC0", "mode0_VC1","mode0_VC2","mode0_VC3";

	/* without PAF HW */
	sensor4_ch_mode0: sensor4-ch-mode0 {
		reg = <0x170C1000 0x100>, /* DMA0 VC0 */
			<0x170C1400 0x100>, /* DMA0 Common */
			<0x170C1100 0x100>, /* DMA0 VC1 */
			<0x170C1400 0x100>, /* DMA0 Common */
			<0x170C1200 0x100>, /* DMA0 VC2 */
			<0x170C1400 0x100>, /* DMA0 Common */
			<0x170C1300 0x100>, /* DMA0 VC3 */
			<0x170C1400 0x100>; /* DMA0 Common */
		mux_reg = <0x17020414 0x4>; /* DMA0 input mux */
	};
};

/* REAR TOF */
&is_sensor5 {
	#address-cells = <1>;
	#size-cells = <1>;

	reg = <0x0 0x17080000 0x1000>, /* MIPI-CSI5 */
	<0x0 0x170D0000 0x10000>; /* PHY: M0S4S4S4S4S4S2 */

	phys = <&mipi_phy_csis5_m0s4s4s4s4s4s2 0>;
	scenario = <SENSOR_SCENARIO_VISION>;    /* Normal, Vision, OIS etc */
	id =  <3>;

	csi_ch = <5>;
	dma_ch = <1 1 1 1>;
	vc_ch = <0 1 2 3>;
	flite_ch = <FLITE_ID_NOTHING>;
	is_bns = <0>;
	status = "okay";

	interrupts = <0 INTREQ__CSIS5 IRQ_TYPE_LEVEL_HIGH>, /* MIPI-CSI5 */
			<0 INTREQ__CSIS_DMA1 IRQ_TYPE_LEVEL_HIGH>,
			<0 INTREQ__CSIS_DMA1 IRQ_TYPE_LEVEL_HIGH>,
			<0 INTREQ__CSIS_DMA1 IRQ_TYPE_LEVEL_HIGH>,
			<0 INTREQ__CSIS_DMA1 IRQ_TYPE_LEVEL_HIGH>;

	/* without PAF HW */
	sensor5_ch_mode0: sensor5-ch-mode0 {
		reg = <0x170C2000 0x100>, /* DMA1 VC0 */
			<0x170C2400 0x100>, /* DMA1 Common */
			<0x170C2100 0x100>, /* DMA1 VC1 */
			<0x170C2400 0x100>, /* DMA1 Common */
			<0x170C2200 0x100>, /* DMA1 VC2 */
			<0x170C2400 0x100>, /* DMA1 Common */
			<0x170C2300 0x100>, /* DMA1 VC3 */
			<0x170C2400 0x100>; /* DMA1 Common */
		mux_reg = <0x17020418 0x4>; /* DMA1 input mux */
	};
};

&exynos_is {
	vender {
		rear_sensor_id = <52>;	/* 2LD */
		front_sensor_id = <38>; /* 3J1 */
		rear2_sensor_id = <54>;	/* GW2 */
		rear3_sensor_id = <53>; /* 2LA */
		rear_tof_sensor_id = <119>; /* IMX516 */
		use_module_check;
		use_ois;
		check_sensor_vendor;
		ois_sensor_index = <0>;
		aperture_sensor_index = <0>;
		mcu_sensor_index = <0>;

		/* max_supported_camera = <10>; */
		/* supported_cameraId = <0 1 20 21 22 23 50 51 52 80>; */
		/* REAR, FRONT, DUAL_REAR_ZOOM, TELE, FRONT_PORTRAIT, WIDE, REAR_2ND, FRONT_2ND, REAR_3RD */
		max_supported_camera = <3>;
		supported_cameraId = <0 1 80>;
		/* REAR, FRONT, REAR_TOF */

		/* sysfs camera id */
		max_camera_num = <9>;
		camera_info0 {			// 0 : sysfs rear
			internal_id = <0>;	// 0 : wide
			isp = <0>;			/* 0 : INT , 1 : EXT , 2 : SOC */
			cal_memory = <2>;	/* 0 : N , 1 : FROM , 2 : EEPROM , 3 : OTP  */
			read_version = <0>;	/* 0 : SYSFS , 1 : CAMON */
			core_voltage = <0>;	/* 0 : N , 1 : Y  */
			upgrade = <0>;		/* 0 : N , 1 : SYSFS , 2 : CAMON */
			fw_write = <0>;		/* 0 : N,  1 : OS, 2 : SD, 3 : ALL */
			fw_dump = <0>;		/* 0 : N , 1 : Y  */
			companion = <0>;	/* 0 : N , 1 : Y  */
			ois = <1>;			/* 0 : N , 1 : Y  */
			valid = <1>;		/* 0 : INVALID , 1 : VALID   */
		};
		camera_info1 {			// 1 : sysfs front
			internal_id = <1>;	// 1 : front master
			isp = <0>;			/* 0 : INT , 1 : EXT , 2 : SOC */
			cal_memory = <2>;	/* 0 : N , 1 : FROM , 2 : EEPROM , 3 : OTP  */
			read_version = <0>;	/* 0 : SYSFS , 1 : CAMON */
			core_voltage = <0>;	/* 0 : N , 1 : Y  */
			upgrade = <0>;		/* 0 : N , 1 : SYSFS , 2 : CAMON */
			fw_write = <0>;		/* 0 : N,  1 : OS, 2 : SD, 3 : ALL */
			fw_dump = <0>;		/* 0 : N , 1 : Y  */
			companion = <0>;	/* 0 : N , 1 : Y  */
			ois = <0>;			/* 0 : N , 1 : Y  */
			valid = <1>;		/* 0 : INVALID , 1 : VALID   */
		};
		camera_info2 {			// 2 : sysfs rear2
			internal_id = <4>;	// 4 : ultra wide
			isp = <0>;			/* 0 : INT , 1 : EXT , 2 : SOC */
			cal_memory = <2>;	/* 0 : N , 1 : FROM , 2 : EEPROM , 3 : OTP  */
			read_version = <0>;	/* 0 : SYSFS , 1 : CAMON */
			core_voltage = <0>;	/* 0 : N , 1 : Y  */
			upgrade = <0>;		/* 0 : N , 1 : SYSFS , 2 : CAMON */
			fw_write = <0>;		/* 0 : N,  1 : OS, 2 : SD, 3 : ALL */
			fw_dump = <0>;		/* 0 : N , 1 : Y  */
			companion = <0>;	/* 0 : N , 1 : Y  */
			ois = <0>;			/* 0 : N , 1 : Y  */
			valid = <1>;		/* 0 : INVALID , 1 : VALID   */
		};
		camera_info3 {			// 3 : sysfs front2
			internal_id = <3>;	// 3 : front sub
			isp = <0>;			/* 0 : INT , 1 : EXT , 2 : SOC */
			cal_memory = <2>;	/* 0 : N , 1 : FROM , 2 : EEPROM , 3 : OTP  */
			read_version = <0>;	/* 0 : SYSFS , 1 : CAMON */
			core_voltage = <0>;	/* 0 : N , 1 : Y  */
			upgrade = <0>;		/* 0 : N , 1 : SYSFS , 2 : CAMON */
			fw_write = <0>;		/* 0 : N,  1 : OS, 2 : SD, 3 : ALL */
			fw_dump = <0>;		/* 0 : N , 1 : Y  */
			companion = <0>;	/* 0 : N , 1 : Y  */
			ois = <0>;			/* 0 : N , 1 : Y  */
			valid = <1>;		/* 0 : INVALID , 1 : VALID   */
		};
		camera_info4 {			// 4 : sysfs rear3
			internal_id = <2>;	// 4 : tele
			isp = <0>;			/* 0 : INT , 1 : EXT , 2 : SOC */
			cal_memory = <2>;	/* 0 : N , 1 : FROM , 2 : EEPROM , 3 : OTP  */
			read_version = <0>;	/* 0 : SYSFS , 1 : CAMON */
			core_voltage = <0>;	/* 0 : N , 1 : Y  */
			upgrade = <0>;		/* 0 : N , 1 : SYSFS , 2 : CAMON */
			fw_write = <0>;		/* 0 : N,  1 : OS, 2 : SD, 3 : ALL */
			fw_dump = <0>;		/* 0 : N , 1 : Y  */
			companion = <0>;	/* 0 : N , 1 : Y  */
			ois = <1>;			/* 0 : N , 1 : Y  */
			valid = <1>;		/* 0 : INVALID , 1 : VALID   */
		};
		camera_info5 {			// 5 : sysfs front3
			valid = <0>;		/* 0 : INVALID , 1 : VALID   */
		};
		camera_info6 {			// 6 : sysfs rear4
			valid = <0>;		/* 0 : INVALID , 1 : VALID   */
		};
		camera_info7 {			// 7 : sysfs front4
			valid = <0>;		/* 0 : INVALID , 1 : VALID   */
		};
		camera_info8 {			// 8 : sysfs rear tof
			internal_id = <8>;	// 3 : rear tof
			isp = <0>;			/* 0 : INT , 1 : EXT , 2 : SOC */
			cal_memory = <2>;	/* 0 : N , 1 : FROM , 2 : EEPROM , 3 : OTP  */
			read_version = <0>;	/* 0 : SYSFS , 1 : CAMON */
			core_voltage = <0>;	/* 0 : N , 1 : Y  */
			upgrade = <0>;		/* 0 : N , 1 : SYSFS , 2 : CAMON */
			fw_write = <0>;		/* 0 : N,  1 : OS, 2 : SD, 3 : ALL */
			fw_dump = <0>;		/* 0 : N , 1 : Y  */
			companion = <0>;	/* 0 : N , 1 : Y  */
			ois = <0>;			/* 0 : N , 1 : Y  */
			valid = <1>;		/* 0 : INVALID , 1 : VALID   */
		};
	};

	lic_offsets {
		/* 3AA = <setA lic offset0, setA lic offset1, set A trigger context */
		/*		setB lic offset0, setB lic offset1, set B trigger context> */
		/* 4672: 4640x4352 */
		/* 5824: 5804x4352 */
		3AA = <6848 13696 1 6848 13696 2>;
	};

	is_dvfs {
		#define DVFS_INT_CAM_L0 690000
		#define DVFS_INT_CAM_L1 680000
		#define DVFS_INT_CAM_L2 670000
		#define DVFS_INT_CAM_L3 660000
		#define DVFS_INT_CAM_L4 650000
		#define DVFS_INT_CAM_L5 640000
		#define DVFS_INT_CAM_L6 630000
		#define DVFS_INT_CAM_L7 620000

		#define DVFS_TNR_L0 690000
		#define DVFS_TNR_L1 680000
		#define DVFS_TNR_L2 670000
		#define DVFS_TNR_L3 660000
		#define DVFS_TNR_L4 650000
		#define DVFS_TNR_L5 640000
		#define DVFS_TNR_L6 630000
		#define DVFS_TNR_L7 620000

		#define DVFS_INT_L0 533000
		#define DVFS_INT_L1 400000
		#define DVFS_INT_L2 333000
		#define DVFS_INT_L3 266000
		#define DVFS_INT_L4 200000
		#define DVFS_INT_L5 133000

		#define DVFS_CAM_L0 690000
		#define DVFS_CAM_L1 680000
		#define DVFS_CAM_L2 670000
		#define DVFS_CAM_L3 660000
		#define DVFS_CAM_L4 650000
		#define DVFS_CAM_L5 640000

		#define DVFS_MIF_L0 2730000
		#define DVFS_MIF_L1 2535000
		#define DVFS_MIF_L2 2288000
		#define DVFS_MIF_L3 2028000
		#define DVFS_MIF_L4 1716000
		#define DVFS_MIF_L5 1539000
		#define DVFS_MIF_L6 1352000
		#define DVFS_MIF_L7 1014000
		#define DVFS_MIF_L8 845000
		#define DVFS_MIF_L9 676000
		#define DVFS_MIF_L10 546000
		#define DVFS_MIF_L11 421000

		table0 {
			desc = "dvfs table v0.3.0 v1.0 for 12M/16M";

			default_int_cam = <DVFS_INT_CAM_L3>;
			default_tnr = <DVFS_TNR_L3>;
			default_cam = <DVFS_CAM_L0>;
			default_mif = <DVFS_MIF_L0>;
			default_int = <DVFS_INT_L0>;
			default_hpg = <1>;

			front2_preview_int_cam = <DVFS_INT_CAM_L5>;
			front2_preview_tnr = <DVFS_TNR_L5>;
			front2_preview_cam = <DVFS_CAM_L4>;
			front2_preview_mif = <DVFS_MIF_L3>;
			front2_preview_int = <DVFS_INT_L4>;
			front2_preview_hpg = <1>;

			front2_capture_int_cam = <DVFS_INT_CAM_L3>;
			front2_capture_tnr = <DVFS_TNR_L3>;
			front2_capture_cam = <DVFS_CAM_L4>;
			front2_capture_mif = <DVFS_MIF_L0>;
			front2_capture_int = <DVFS_INT_L4>;
			front2_capture_hpg = <1>;

			front2_video_int_cam = <DVFS_INT_CAM_L5>;
			front2_video_tnr = <DVFS_TNR_L5>;
			front2_video_cam = <DVFS_CAM_L4>;
			front2_video_mif = <DVFS_MIF_L5>;
			front2_video_int = <DVFS_INT_L4>;
			front2_video_hpg = <1>;

			front2_video_capture_int_cam = <DVFS_INT_CAM_L3>;
			front2_video_capture_tnr = <DVFS_TNR_L3>;
			front2_video_capture_cam = <DVFS_CAM_L4>;
			front2_video_capture_mif = <DVFS_MIF_L0>;
			front2_video_capture_int = <DVFS_INT_L4>;
			front2_video_capture_hpg = <1>;

			front_preview_int_cam = <DVFS_INT_CAM_L5>;
			front_preview_tnr = <DVFS_TNR_L5>;
			front_preview_cam = <DVFS_CAM_L4>;
			front_preview_mif = <DVFS_MIF_L6>;
			front_preview_int = <DVFS_INT_L4>;
			front_preview_hpg = <1>;

			front_preview_full_int_cam = <DVFS_INT_CAM_L5>;
			front_preview_full_tnr = <DVFS_TNR_L5>;
			front_preview_full_cam = <DVFS_CAM_L4>;
			front_preview_full_mif = <DVFS_MIF_L5>;
			front_preview_full_int = <DVFS_INT_L4>;
			front_preview_full_hpg = <1>;

			front_capture_int_cam = <DVFS_INT_CAM_L3>;
			front_capture_tnr = <DVFS_TNR_L3>;
			front_capture_cam = <DVFS_CAM_L4>;
			front_capture_mif = <DVFS_MIF_L0>;
			front_capture_int = <DVFS_INT_L4>;
			front_capture_hpg = <1>;

			front_video_int_cam = <DVFS_INT_CAM_L5>;
			front_video_tnr = <DVFS_TNR_L5>;
			front_video_cam = <DVFS_CAM_L4>;
			front_video_mif = <DVFS_MIF_L5>;
			front_video_int = <DVFS_INT_L4>;
			front_video_hpg = <1>;

			front_video_whd_int_cam = <DVFS_INT_CAM_L5>;
			front_video_whd_tnr = <DVFS_TNR_L5>;
			front_video_whd_cam = <DVFS_CAM_L4>;
			front_video_whd_mif = <DVFS_MIF_L5>;
			front_video_whd_int = <DVFS_INT_L4>;
			front_video_whd_hpg = <1>;

			front_video_uhd_int_cam = <DVFS_INT_CAM_L5>;
			front_video_uhd_tnr = <DVFS_TNR_L5>;
			front_video_uhd_cam = <DVFS_CAM_L4>;
			front_video_uhd_mif = <DVFS_MIF_L5>;
			front_video_uhd_int = <DVFS_INT_L4>;
			front_video_uhd_hpg = <1>;

			front_video_fhd_60fps_int_cam = <DVFS_INT_CAM_L5>;
			front_video_fhd_60fps_tnr = <DVFS_TNR_L5>;
			front_video_fhd_60fps_cam = <DVFS_CAM_L4>;
			front_video_fhd_60fps_mif = <DVFS_MIF_L5>;
			front_video_fhd_60fps_int = <DVFS_INT_L4>;
			front_video_fhd_60fps_hpg = <1>;

			front_video_uhd_60fps_int_cam = <DVFS_INT_CAM_L4>;
			front_video_uhd_60fps_tnr = <DVFS_TNR_L4>;
			front_video_uhd_60fps_cam = <DVFS_CAM_L4>;
			front_video_uhd_60fps_mif = <DVFS_MIF_L5>;
			front_video_uhd_60fps_int = <DVFS_INT_L4>;
			front_video_uhd_60fps_hpg = <1>;

			front_video_fhd_120fps_int_cam = <DVFS_INT_CAM_L3>;
			front_video_fhd_120fps_tnr = <DVFS_TNR_L3>;
			front_video_fhd_120fps_cam = <DVFS_CAM_L2>;
			front_video_fhd_120fps_mif = <DVFS_MIF_L3>;
			front_video_fhd_120fps_int = <DVFS_INT_L2>;
			front_video_fhd_120fps_hpg = <1>;

			front_video_capture_int_cam = <DVFS_INT_CAM_L3>;
			front_video_capture_tnr = <DVFS_TNR_L3>;
			front_video_capture_cam = <DVFS_CAM_L4>;
			front_video_capture_mif = <DVFS_MIF_L0>;
			front_video_capture_int = <DVFS_INT_L4>;
			front_video_capture_hpg = <1>;

			front_video_whd_capture_int_cam = <DVFS_INT_CAM_L3>;
			front_video_whd_capture_tnr = <DVFS_TNR_L3>;
			front_video_whd_capture_cam = <DVFS_CAM_L4>;
			front_video_whd_capture_mif = <DVFS_MIF_L0>;
			front_video_whd_capture_int = <DVFS_INT_L4>;
			front_video_whd_capture_hpg = <1>;

			front_video_uhd_capture_int_cam = <DVFS_INT_CAM_L3>;
			front_video_uhd_capture_tnr = <DVFS_TNR_L3>;
			front_video_uhd_capture_cam = <DVFS_CAM_L4>;
			front_video_uhd_capture_mif = <DVFS_MIF_L0>;
			front_video_uhd_capture_int = <DVFS_INT_L4>;
			front_video_uhd_capture_hpg = <1>;

			front_video_uhd_60fps_capture_int_cam = <DVFS_INT_CAM_L3>;
			front_video_uhd_60fps_capture_tnr = <DVFS_TNR_L3>;
			front_video_uhd_60fps_capture_cam = <DVFS_CAM_L4>;
			front_video_uhd_60fps_capture_mif = <DVFS_MIF_L3>;
			front_video_uhd_60fps_capture_int = <DVFS_INT_L4>;
			front_video_uhd_60fps_capture_hpg = <1>;

			front_video_fhd_60fps_capture_int_cam = <DVFS_INT_CAM_L3>;
			front_video_fhd_60fps_capture_tnr = <DVFS_TNR_L3>;
			front_video_fhd_60fps_capture_cam = <DVFS_CAM_L4>;
			front_video_fhd_60fps_capture_mif = <DVFS_MIF_L3>;
			front_video_fhd_60fps_capture_int = <DVFS_INT_L4>;
			front_video_fhd_60fps_capture_hpg = <1>;

			front_video_fhd_120fps_capture_int_cam = <DVFS_INT_CAM_L3>;
			front_video_fhd_120fps_capture_tnr = <DVFS_TNR_L3>;
			front_video_fhd_120fps_capture_cam = <DVFS_CAM_L2>;
			front_video_fhd_120fps_capture_mif = <DVFS_MIF_L0>;
			front_video_fhd_120fps_capture_int = <DVFS_INT_L2>;
			front_video_fhd_120fps_capture_hpg = <1>;

			front_dual_sync_preview_int_cam = <DVFS_INT_CAM_L5>;
			front_dual_sync_preview_tnr = <DVFS_TNR_L5>;
			front_dual_sync_preview_cam = <DVFS_CAM_L4>;
			front_dual_sync_preview_mif = <DVFS_MIF_L3>;
			front_dual_sync_preview_int = <DVFS_INT_L4>;
			front_dual_sync_preview_hpg = <1>;

			front_dual_sync_capture_int_cam = <DVFS_INT_CAM_L3>;
			front_dual_sync_capture_tnr = <DVFS_TNR_L3>;
			front_dual_sync_capture_cam = <DVFS_CAM_L4>;
			front_dual_sync_capture_mif = <DVFS_MIF_L3>;
			front_dual_sync_capture_int = <DVFS_INT_L4>;
			front_dual_sync_capture_hpg = <1>;

			front_dual_sync_video_fhd_int_cam = <DVFS_INT_CAM_L5>;
			front_dual_sync_video_fhd_tnr = <DVFS_TNR_L5>;
			front_dual_sync_video_fhd_cam = <DVFS_CAM_L4>;
			front_dual_sync_video_fhd_mif = <DVFS_MIF_L3>;
			front_dual_sync_video_fhd_int = <DVFS_INT_L4>;
			front_dual_sync_video_fhd_hpg = <1>;

			front_dual_sync_video_fhd_capture_int_cam = <DVFS_INT_CAM_L3>;
			front_dual_sync_video_fhd_capture_tnr = <DVFS_TNR_L3>;
			front_dual_sync_video_fhd_capture_cam = <DVFS_CAM_L4>;
			front_dual_sync_video_fhd_capture_mif = <DVFS_MIF_L3>;
			front_dual_sync_video_fhd_capture_int = <DVFS_INT_L4>;
			front_dual_sync_video_fhd_capture_hpg = <1>;

			front_vt1_int_cam = <DVFS_INT_CAM_L5>;
			front_vt1_tnr = <DVFS_TNR_L5>;
			front_vt1_cam = <DVFS_CAM_L4>;
			front_vt1_mif = <DVFS_MIF_L7>;
			front_vt1_int = <DVFS_INT_L4>;
			front_vt1_hpg = <1>;

			front_vt2_int_cam = <DVFS_INT_CAM_L5>;
			front_vt2_tnr = <DVFS_TNR_L5>;
			front_vt2_cam = <DVFS_CAM_L4>;
			front_vt2_mif = <DVFS_MIF_L7>;
			front_vt2_int = <DVFS_INT_L4>;
			front_vt2_hpg = <1>;

			front_vt4_int_cam = <DVFS_INT_CAM_L5>;
			front_vt4_tnr = <DVFS_TNR_L5>;
			front_vt4_cam = <DVFS_CAM_L4>;
			front_vt4_mif = <DVFS_MIF_L7>;
			front_vt4_int = <DVFS_INT_L4>;
			front_vt4_hpg = <1>;

			front_preview_high_speed_fps_int_cam = <DVFS_INT_CAM_L1>;
			front_preview_high_speed_fps_tnr = <DVFS_TNR_L1>;
			front_preview_high_speed_fps_cam = <DVFS_CAM_L1>;
			front_preview_high_speed_fps_mif = <DVFS_MIF_L1>;
			front_preview_high_speed_fps_int = <DVFS_INT_L1>;
			front_preview_high_speed_fps_hpg = <1>;

			front_video_high_speed_120fps_int_cam = <DVFS_INT_CAM_L3>;
			front_video_high_speed_120fps_tnr = <DVFS_TNR_L3>;
			front_video_high_speed_120fps_cam = <DVFS_CAM_L3>;	/* X1/Y2/C2 CAM(L4), Z3 CAM(L3) */
			front_video_high_speed_120fps_mif = <DVFS_MIF_L3>;
			front_video_high_speed_120fps_int = <DVFS_INT_L4>;
			front_video_high_speed_120fps_hpg = <1>;

			rear3_preview_fhd_int_cam = <DVFS_INT_CAM_L3>;
			rear3_preview_fhd_tnr = <DVFS_TNR_L3>;
			rear3_preview_fhd_cam = <DVFS_CAM_L1>;	/* OTF */
			rear3_preview_fhd_mif = <DVFS_MIF_L3>;
			rear3_preview_fhd_int = <DVFS_INT_L2>;
			rear3_preview_fhd_hpg = <1>;

			rear3_capture_int_cam = <DVFS_INT_CAM_L3>;
			rear3_capture_tnr = <DVFS_TNR_L3>;
			rear3_capture_cam = <DVFS_CAM_L1>;		/* OTF */
			rear3_capture_mif = <DVFS_MIF_L0>;
			rear3_capture_int = <DVFS_INT_L2>;
			rear3_capture_hpg = <1>;

			rear3_video_fhd_int_cam = <DVFS_INT_CAM_L5>;
			rear3_video_fhd_tnr = <DVFS_TNR_L5>;
			rear3_video_fhd_cam = <DVFS_CAM_L1>;	/* OTF */
			rear3_video_fhd_mif = <DVFS_MIF_L5>;
			rear3_video_fhd_int = <DVFS_INT_L2>;
			rear3_video_fhd_hpg = <1>;

			rear3_video_fhd_capture_int_cam = <DVFS_INT_CAM_L3>;
			rear3_video_fhd_capture_tnr = <DVFS_TNR_L3>;
			rear3_video_fhd_capture_cam = <DVFS_CAM_L1>;	/* OTF */
			rear3_video_fhd_capture_mif = <DVFS_MIF_L0>;
			rear3_video_fhd_capture_int = <DVFS_INT_L2>;
			rear3_video_fhd_capture_hpg = <1>;

			rear2_preview_fhd_int_cam = <DVFS_INT_CAM_L3>;
			rear2_preview_fhd_tnr = <DVFS_TNR_L3>;
			rear2_preview_fhd_cam = <DVFS_CAM_L1>;	/* OTF */
			rear2_preview_fhd_mif = <DVFS_MIF_L3>;
			rear2_preview_fhd_int = <DVFS_INT_L2>;
			rear2_preview_fhd_hpg = <1>;

			rear2_capture_int_cam = <DVFS_INT_CAM_L3>;
			rear2_capture_tnr = <DVFS_TNR_L3>;
			rear2_capture_cam = <DVFS_CAM_L1>;	/* OTF */
			rear2_capture_mif = <DVFS_MIF_L0>;
			rear2_capture_int = <DVFS_INT_L2>;
			rear2_capture_hpg = <1>;

			rear2_video_fhd_int_cam = <DVFS_INT_CAM_L5>;
			rear2_video_fhd_tnr = <DVFS_TNR_L5>;
			rear2_video_fhd_cam = <DVFS_CAM_L1>;	/* OTF */
			rear2_video_fhd_mif = <DVFS_MIF_L5>;
			rear2_video_fhd_int = <DVFS_INT_L2>;
			rear2_video_fhd_hpg = <1>;

			rear2_video_uhd_8k_int_cam = <DVFS_INT_CAM_L3>;
			rear2_video_uhd_8k_tnr = <DVFS_TNR_L3>;
			rear2_video_uhd_8k_cam = <DVFS_CAM_L1>;	/* OTF */
			rear2_video_uhd_8k_mif = <DVFS_MIF_L3>;
			rear2_video_uhd_8k_int = <DVFS_INT_L2>;
			rear2_video_uhd_8k_hpg = <1>;

			rear2_video_fhd_capture_int_cam = <DVFS_INT_CAM_L3>;
			rear2_video_fhd_capture_tnr = <DVFS_TNR_L3>;
			rear2_video_fhd_capture_cam = <DVFS_CAM_L1>;	/* OTF */
			rear2_video_fhd_capture_mif = <DVFS_MIF_L0>;
			rear2_video_fhd_capture_int = <DVFS_INT_L2>;
			rear2_video_fhd_capture_hpg = <1>;

			rear2_video_uhd_8k_capture_int_cam = <DVFS_INT_CAM_L2>;
			rear2_video_uhd_8k_capture_tnr = <DVFS_TNR_L2>;
			rear2_video_uhd_8k_capture_cam = <DVFS_CAM_L1>;	/* OTF */
			rear2_video_uhd_8k_capture_mif = <DVFS_MIF_L0>;
			rear2_video_uhd_8k_capture_int = <DVFS_INT_L0>;
			rear2_video_uhd_8k_capture_hpg = <1>;

			rear_preview_fhd_int_cam = <DVFS_INT_CAM_L3>;
			rear_preview_fhd_tnr = <DVFS_TNR_L3>;
			rear_preview_fhd_cam = <DVFS_CAM_L1>;	/* VOTF */
			rear_preview_fhd_mif = <DVFS_MIF_L3>;
			rear_preview_fhd_int = <DVFS_INT_L2>;
			rear_preview_fhd_hpg = <1>;

			rear_preview_whd_int_cam = <DVFS_INT_CAM_L3>;
			rear_preview_whd_tnr = <DVFS_TNR_L3>;
			rear_preview_whd_cam = <DVFS_CAM_L1>;	/* VOTF */
			rear_preview_whd_mif = <DVFS_MIF_L3>;
			rear_preview_whd_int = <DVFS_INT_L2>;
			rear_preview_whd_hpg = <1>;

			rear_preview_uhd_int_cam = <DVFS_INT_CAM_L3>;
			rear_preview_uhd_tnr = <DVFS_TNR_L3>;
			rear_preview_uhd_cam = <DVFS_CAM_L1>;	/* VOTF */
			rear_preview_uhd_mif = <DVFS_MIF_L3>;
			rear_preview_uhd_int = <DVFS_INT_L2>;
			rear_preview_uhd_hpg = <1>;

			rear_preview_uhd_60fps_int_cam = <DVFS_INT_CAM_L3>;
			rear_preview_uhd_60fps_tnr = <DVFS_TNR_L2>;
			rear_preview_uhd_60fps_cam = <DVFS_CAM_L1>;	/* VOTF */
			rear_preview_uhd_60fps_mif = <DVFS_MIF_L3>;
			rear_preview_uhd_60fps_int = <DVFS_INT_L2>;
			rear_preview_uhd_60fps_hpg = <1>;

			rear_preview_full_int_cam = <DVFS_INT_CAM_L3>;
			rear_preview_full_tnr = <DVFS_TNR_L3>;
			rear_preview_full_cam = <DVFS_CAM_L1>;	/* VOTF */
			rear_preview_full_mif = <DVFS_MIF_L3>;
			rear_preview_full_int = <DVFS_INT_L2>;
			rear_preview_full_hpg = <1>;

			rear_capture_int_cam = <DVFS_INT_CAM_L3>;
			rear_capture_tnr = <DVFS_TNR_L3>;
			rear_capture_cam = <DVFS_CAM_L1>;	/* VOTF */
			rear_capture_mif = <DVFS_MIF_L0>;
			rear_capture_int = <DVFS_INT_L2>;
			rear_capture_hpg = <1>;

			rear_video_fhd_int_cam = <DVFS_INT_CAM_L5>;
			rear_video_fhd_tnr = <DVFS_TNR_L5>;
			rear_video_fhd_cam = <DVFS_CAM_L2>;	/* VOTF */
			rear_video_fhd_mif = <DVFS_MIF_L6>;
			rear_video_fhd_int = <DVFS_INT_L3>;
			rear_video_fhd_hpg = <1>;

			rear_video_hdr_int_cam = <DVFS_INT_CAM_L5>;
			rear_video_hdr_tnr = <DVFS_TNR_L5>;
			rear_video_hdr_cam = <DVFS_CAM_L1>;	/* VOTF */
			rear_video_hdr_mif = <DVFS_MIF_L5>;
			rear_video_hdr_int = <DVFS_INT_L2>;
			rear_video_hdr_hpg = <1>;

			rear_video_whd_int_cam = <DVFS_INT_CAM_L3>;
			rear_video_whd_tnr = <DVFS_TNR_L3>;
			rear_video_whd_cam = <DVFS_CAM_L1>;	/* VOTF */
			rear_video_whd_mif = <DVFS_MIF_L5>;
			rear_video_whd_int = <DVFS_INT_L2>;
			rear_video_whd_hpg = <1>;

			rear_video_uhd_int_cam = <DVFS_INT_CAM_L5>;
			rear_video_uhd_tnr = <DVFS_TNR_L5>;
			rear_video_uhd_cam = <DVFS_CAM_L2>;	/* VOTF */
			rear_video_uhd_mif = <DVFS_MIF_L5>;
			rear_video_uhd_int = <DVFS_INT_L3>;
			rear_video_uhd_hpg = <1>;

			rear_video_uhd_60fps_int_cam = <DVFS_INT_CAM_L3>;
			rear_video_uhd_60fps_tnr = <DVFS_TNR_L3>;
			rear_video_uhd_60fps_cam = <DVFS_CAM_L1>;	/* OTF */
			rear_video_uhd_60fps_mif = <DVFS_MIF_L5>;
			rear_video_uhd_60fps_int = <DVFS_INT_L3>;
			rear_video_uhd_60fps_hpg = <1>;

			rear_video_uhd_8k_int_cam = <DVFS_INT_CAM_L3>;
			rear_video_uhd_8k_tnr = <DVFS_TNR_L3>;
			rear_video_uhd_8k_cam = <DVFS_CAM_L1>;	/* VOTF */
			rear_video_uhd_8k_mif = <DVFS_MIF_L3>;
			rear_video_uhd_8k_int = <DVFS_INT_L2>;
			rear_video_uhd_8k_hpg = <1>;

			rear_video_fhd_capture_int_cam = <DVFS_INT_CAM_L3>;
			rear_video_fhd_capture_tnr = <DVFS_TNR_L3>;
			rear_video_fhd_capture_cam = <DVFS_CAM_L1>;	/* VOTF */
			rear_video_fhd_capture_mif = <DVFS_MIF_L0>;
			rear_video_fhd_capture_int = <DVFS_INT_L2>;
			rear_video_fhd_capture_hpg = <1>;

			rear_video_hdr_capture_int_cam = <DVFS_INT_CAM_L3>;
			rear_video_hdr_capture_tnr = <DVFS_TNR_L3>;
			rear_video_hdr_capture_cam = <DVFS_CAM_L1>;	/* VOTF */
			rear_video_hdr_capture_mif = <DVFS_MIF_L0>;
			rear_video_hdr_capture_int = <DVFS_INT_L2>;
			rear_video_hdr_capture_hpg = <1>;

			rear_video_whd_capture_int_cam = <DVFS_INT_CAM_L3>;
			rear_video_whd_capture_tnr = <DVFS_TNR_L3>;
			rear_video_whd_capture_cam = <DVFS_CAM_L1>;	/* VOTF */
			rear_video_whd_capture_mif = <DVFS_MIF_L0>;
			rear_video_whd_capture_int = <DVFS_INT_L2>;
			rear_video_whd_capture_hpg = <1>;

			rear_video_uhd_capture_int_cam = <DVFS_INT_CAM_L3>;
			rear_video_uhd_capture_tnr = <DVFS_TNR_L3>;
			rear_video_uhd_capture_cam = <DVFS_CAM_L1>;	/* VOTF */
			rear_video_uhd_capture_mif = <DVFS_MIF_L0>;
			rear_video_uhd_capture_int = <DVFS_INT_L2>;
			rear_video_uhd_capture_hpg = <1>;

			rear_video_uhd_8k_capture_int_cam = <DVFS_INT_CAM_L2>;
			rear_video_uhd_8k_capture_tnr = <DVFS_TNR_L2>;
			rear_video_uhd_8k_capture_cam = <DVFS_CAM_L1>;	/* VOTF */
			rear_video_uhd_8k_capture_mif = <DVFS_MIF_L0>;
			rear_video_uhd_8k_capture_int = <DVFS_INT_L0>;
			rear_video_uhd_8k_capture_hpg = <1>;

			dual_preview_int_cam = <DVFS_INT_CAM_L3>;
			dual_preview_tnr = <DVFS_TNR_L3>;
			dual_preview_cam = <DVFS_CAM_L1>;	/* OTF */
			dual_preview_mif = <DVFS_MIF_L0>;
			dual_preview_int = <DVFS_INT_L0>;
			dual_preview_hpg = <1>;

			dual_capture_int_cam = <DVFS_INT_CAM_L3>;
			dual_capture_tnr = <DVFS_TNR_L3>;
			dual_capture_cam = <DVFS_CAM_L1>;	/* OTF */
			dual_capture_mif = <DVFS_MIF_L0>;
			dual_capture_int = <DVFS_INT_L0>;
			dual_capture_hpg = <1>;

			dual_video_fhd_int_cam = <DVFS_INT_CAM_L3>;
			dual_video_fhd_tnr = <DVFS_TNR_L3>;
			dual_video_fhd_cam = <DVFS_CAM_L1>;	/* OTF */
			dual_video_fhd_mif = <DVFS_MIF_L3>;
			dual_video_fhd_int = <DVFS_INT_L0>;
			dual_video_fhd_hpg = <1>;

			dual_video_fhd_capture_int_cam = <DVFS_INT_CAM_L3>;
			dual_video_fhd_capture_tnr = <DVFS_TNR_L3>;
			dual_video_fhd_capture_cam = <DVFS_CAM_L1>;	/* OTF */
			dual_video_fhd_capture_mif = <DVFS_MIF_L0>;
			dual_video_fhd_capture_int = <DVFS_INT_L0>;
			dual_video_fhd_capture_hpg = <1>;

			dual_video_uhd_int_cam = <DVFS_INT_CAM_L3>;
			dual_video_uhd_tnr = <DVFS_TNR_L3>;
			dual_video_uhd_cam = <DVFS_CAM_L1>;	/* OTF */
			dual_video_uhd_mif = <DVFS_MIF_L3>;
			dual_video_uhd_int = <DVFS_INT_L0>;
			dual_video_uhd_hpg = <1>;

			dual_video_uhd_capture_int_cam = <DVFS_INT_CAM_L3>;
			dual_video_uhd_capture_tnr = <DVFS_TNR_L3>;
			dual_video_uhd_capture_cam = <DVFS_CAM_L1>;	/* OTF */
			dual_video_uhd_capture_mif = <DVFS_MIF_L0>;
			dual_video_uhd_capture_int = <DVFS_INT_L0>;
			dual_video_uhd_capture_hpg = <1>;

			dual_sync_preview_int_cam = <DVFS_INT_CAM_L3>;
			dual_sync_preview_tnr = <DVFS_TNR_L3>;
			dual_sync_preview_cam = <DVFS_CAM_L1>;	/* OTF */
			dual_sync_preview_mif = <DVFS_MIF_L0>;
			dual_sync_preview_int = <DVFS_INT_L0>;
			dual_sync_preview_hpg = <1>;

			dual_sync_capture_int_cam = <DVFS_INT_CAM_L3>;
			dual_sync_capture_tnr = <DVFS_TNR_L3>;
			dual_sync_capture_cam = <DVFS_CAM_L1>;	/* OTF */
			dual_sync_capture_mif = <DVFS_MIF_L0>;
			dual_sync_capture_int = <DVFS_INT_L0>;
			dual_sync_capture_hpg = <1>;

			dual_sync_preview_whd_int_cam = <DVFS_INT_CAM_L3>;
			dual_sync_preview_whd_tnr = <DVFS_TNR_L3>;
			dual_sync_preview_whd_cam = <DVFS_CAM_L1>;	/* OTF */
			dual_sync_preview_whd_mif = <DVFS_MIF_L0>;
			dual_sync_preview_whd_int = <DVFS_INT_L0>;
			dual_sync_preview_whd_hpg = <1>;

			dual_sync_whd_capture_int_cam = <DVFS_INT_CAM_L3>;
			dual_sync_whd_capture_tnr = <DVFS_TNR_L3>;
			dual_sync_whd_capture_cam = <DVFS_CAM_L1>;	/* OTF */
			dual_sync_whd_capture_mif = <DVFS_MIF_L0>;
			dual_sync_whd_capture_int = <DVFS_INT_L0>;
			dual_sync_whd_capture_hpg = <1>;

			dual_sync_video_fhd_int_cam = <DVFS_INT_CAM_L3>;
			dual_sync_video_fhd_tnr = <DVFS_TNR_L3>;
			dual_sync_video_fhd_cam = <DVFS_CAM_L0>;	/* OTF */
			dual_sync_video_fhd_mif = <DVFS_MIF_L3>;
			dual_sync_video_fhd_int = <DVFS_INT_L3>;
			dual_sync_video_fhd_hpg = <1>;

			dual_sync_video_fhd_capture_int_cam = <DVFS_INT_CAM_L3>;
			dual_sync_video_fhd_capture_tnr = <DVFS_TNR_L3>;
			dual_sync_video_fhd_capture_cam = <DVFS_CAM_L0>;	/* OTF */
			dual_sync_video_fhd_capture_mif = <DVFS_MIF_L0>;
			dual_sync_video_fhd_capture_int = <DVFS_INT_L0>;
			dual_sync_video_fhd_capture_hpg = <1>;

			dual_sync_video_uhd_int_cam = <DVFS_INT_CAM_L3>;
			dual_sync_video_uhd_tnr = <DVFS_TNR_L3>;
			dual_sync_video_uhd_cam = <DVFS_CAM_L1>;	/* OTF */
			dual_sync_video_uhd_mif = <DVFS_MIF_L3>;
			dual_sync_video_uhd_int = <DVFS_INT_L0>;
			dual_sync_video_uhd_hpg = <1>;

			dual_sync_video_uhd_capture_int_cam = <DVFS_INT_CAM_L3>;
			dual_sync_video_uhd_capture_tnr = <DVFS_TNR_L3>;
			dual_sync_video_uhd_capture_cam = <DVFS_CAM_L1>;	/* OTF */
			dual_sync_video_uhd_capture_mif = <DVFS_MIF_L0>;
			dual_sync_video_uhd_capture_int = <DVFS_INT_L0>;
			dual_sync_video_uhd_capture_hpg = <1>;

			secure_front_int_cam = <DVFS_INT_CAM_L5>;
			secure_front_tnr = <DVFS_TNR_L5>;
			secure_front_cam = <DVFS_CAM_L4>;
			secure_front_mif = <DVFS_MIF_L3>;
			secure_front_int = <DVFS_INT_L3>;
			secure_front_hpg = <1>;

			pip_preview_int_cam = <DVFS_INT_CAM_L3>;
			pip_preview_tnr = <DVFS_TNR_L3>;
			pip_preview_cam = <DVFS_CAM_L1>;
			pip_preview_mif = <DVFS_MIF_L1>;
			pip_preview_int = <DVFS_INT_L0>;
			pip_preview_hpg = <1>;

			pip_capture_int_cam = <DVFS_INT_CAM_L3>;
			pip_capture_tnr = <DVFS_TNR_L3>;
			pip_capture_cam = <DVFS_CAM_L1>;
			pip_capture_mif = <DVFS_MIF_L1>;
			pip_capture_int = <DVFS_INT_L0>;
			pip_capture_hpg = <1>;

			pip_video_int_cam = <DVFS_INT_CAM_L3>;
			pip_video_tnr = <DVFS_TNR_L3>;
			pip_video_cam = <DVFS_CAM_L1>;
			pip_video_mif = <DVFS_MIF_L1>;
			pip_video_int = <DVFS_INT_L0>;
			pip_video_hpg = <1>;

			pip_video_capture_int_cam = <DVFS_INT_CAM_L3>;
			pip_video_capture_tnr = <DVFS_TNR_L3>;
			pip_video_capture_cam = <DVFS_CAM_L1>;
			pip_video_capture_mif = <DVFS_MIF_L1>;
			pip_video_capture_int = <DVFS_INT_L0>;
			pip_video_capture_hpg = <1>;

			preview_high_speed_fps_int_cam = <DVFS_INT_CAM_L1>;
			preview_high_speed_fps_tnr = <DVFS_TNR_L1>;
			preview_high_speed_fps_cam = <DVFS_CAM_L1>;		/* VOTF */
			preview_high_speed_fps_mif = <DVFS_MIF_L1>;
			preview_high_speed_fps_int = <DVFS_INT_L1>;
			preview_high_speed_fps_hpg = <1>;

			video_high_speed_60fps_int_cam = <DVFS_INT_CAM_L5>;
			video_high_speed_60fps_tnr = <DVFS_TNR_L5>;
			video_high_speed_60fps_cam = <DVFS_CAM_L1>;		/* OTF */
			video_high_speed_60fps_mif = <DVFS_MIF_L6>;
			video_high_speed_60fps_int = <DVFS_INT_L3>;
			video_high_speed_60fps_hpg = <1>;

			video_high_speed_60fps_pro_int_cam = <DVFS_INT_CAM_L5>;
			video_high_speed_60fps_pro_tnr = <DVFS_TNR_L5>;
			video_high_speed_60fps_pro_cam = <DVFS_CAM_L1>;         /* OTF */
			video_high_speed_60fps_pro_mif = <DVFS_MIF_L3>;		/* Y2 MIF(L5), C2 MIF(L3) */
			video_high_speed_60fps_pro_int = <DVFS_INT_L3>;
			video_high_speed_60fps_pro_hpg = <1>;

			video_high_speed_120fps_int_cam = <DVFS_INT_CAM_L3>;
			video_high_speed_120fps_tnr = <DVFS_TNR_L3>;
			video_high_speed_120fps_cam = <DVFS_CAM_L1>;	/* VOTF */
			video_high_speed_120fps_mif = <DVFS_MIF_L3>;
			video_high_speed_120fps_int = <DVFS_INT_L2>;
			video_high_speed_120fps_hpg = <1>;

			video_high_speed_120fps_pro_int_cam = <DVFS_INT_CAM_L3>;
			video_high_speed_120fps_pro_tnr = <DVFS_TNR_L3>;
			video_high_speed_120fps_pro_cam = <DVFS_CAM_L1>;        /* VOTF */
			video_high_speed_120fps_pro_mif = <DVFS_MIF_L3>;
			video_high_speed_120fps_pro_int = <DVFS_INT_L2>;
			video_high_speed_120fps_pro_hpg = <1>;

			video_high_speed_240fps_int_cam = <DVFS_INT_CAM_L3>;
			video_high_speed_240fps_tnr = <DVFS_TNR_L3>;
			video_high_speed_240fps_cam = <DVFS_CAM_L1>;	/* VOTF */
			video_high_speed_240fps_mif = <DVFS_MIF_L3>;
			video_high_speed_240fps_int = <DVFS_INT_L2>;
			video_high_speed_240fps_hpg = <1>;

			video_high_speed_480fps_int_cam = <DVFS_INT_CAM_L1>;
			video_high_speed_480fps_tnr = <DVFS_TNR_L1>;
			video_high_speed_480fps_cam = <DVFS_CAM_L1>;	/* VOTF */
			video_high_speed_480fps_mif = <DVFS_MIF_L3>;
			video_high_speed_480fps_int = <DVFS_INT_L2>;
			video_high_speed_480fps_hpg = <1>;

			video_high_speed_960fps_int_cam = <DVFS_INT_CAM_L1>;
			video_high_speed_960fps_tnr = <DVFS_TNR_L1>;
			video_high_speed_960fps_cam = <DVFS_CAM_L1>;	/* VOTF */
			video_high_speed_960fps_mif = <DVFS_MIF_L3>;
			video_high_speed_960fps_int = <DVFS_INT_L2>;
			video_high_speed_960fps_hpg = <1>;

			video_high_speed_dualfps_int_cam = <DVFS_INT_CAM_L3>;
			video_high_speed_dualfps_tnr = <DVFS_TNR_L3>;
			video_high_speed_dualfps_cam = <DVFS_CAM_L1>;	/* VOTF */
			video_high_speed_dualfps_mif = <DVFS_MIF_L3>;
			video_high_speed_dualfps_int = <DVFS_INT_L2>;
			video_high_speed_dualfps_hpg = <6>;

			video_high_speed_60fps_capture_int_cam = <DVFS_INT_CAM_L3>;
			video_high_speed_60fps_capture_tnr = <DVFS_TNR_L3>;
			video_high_speed_60fps_capture_cam = <DVFS_CAM_L1>;	/* OTF */
			video_high_speed_60fps_capture_mif = <DVFS_MIF_L0>;
			video_high_speed_60fps_capture_int = <DVFS_INT_L2>;
			video_high_speed_60fps_capture_hpg = <1>;

			ext_rear_int_cam = <DVFS_INT_CAM_L5>;
			ext_rear_tnr = <DVFS_TNR_L5>;
			ext_rear_cam = <DVFS_CAM_L4>;
			ext_rear_mif = <DVFS_MIF_L3>;
			ext_rear_int = <DVFS_INT_L3>;
			ext_rear_hpg = <1>;

			ext_secure_int_cam = <DVFS_INT_CAM_L5>;
			ext_secure_tnr = <DVFS_TNR_L5>;
			ext_secure_cam = <DVFS_CAM_L4>;
			ext_secure_mif = <DVFS_MIF_L3>;
			ext_secure_int = <DVFS_INT_L3>;
			ext_secure_hpg = <1>;

			thermal_8k_int_cam = <0>;
			thermal_8k_tnr = <0>;
			thermal_8k_cam = <0>;
			thermal_8k_mif = <DVFS_MIF_L3>;
			thermal_8k_int = <0>;
			thermal_8k_hpg = <1>;

			max_int_cam = <DVFS_INT_CAM_L3>;
			max_tnr = <DVFS_TNR_L3>;
			max_cam = <DVFS_CAM_L0>;
			max_mif = <DVFS_MIF_L0>;
			max_int = <DVFS_INT_L0>;
			max_hpg = <1>;
		};
	};
};
